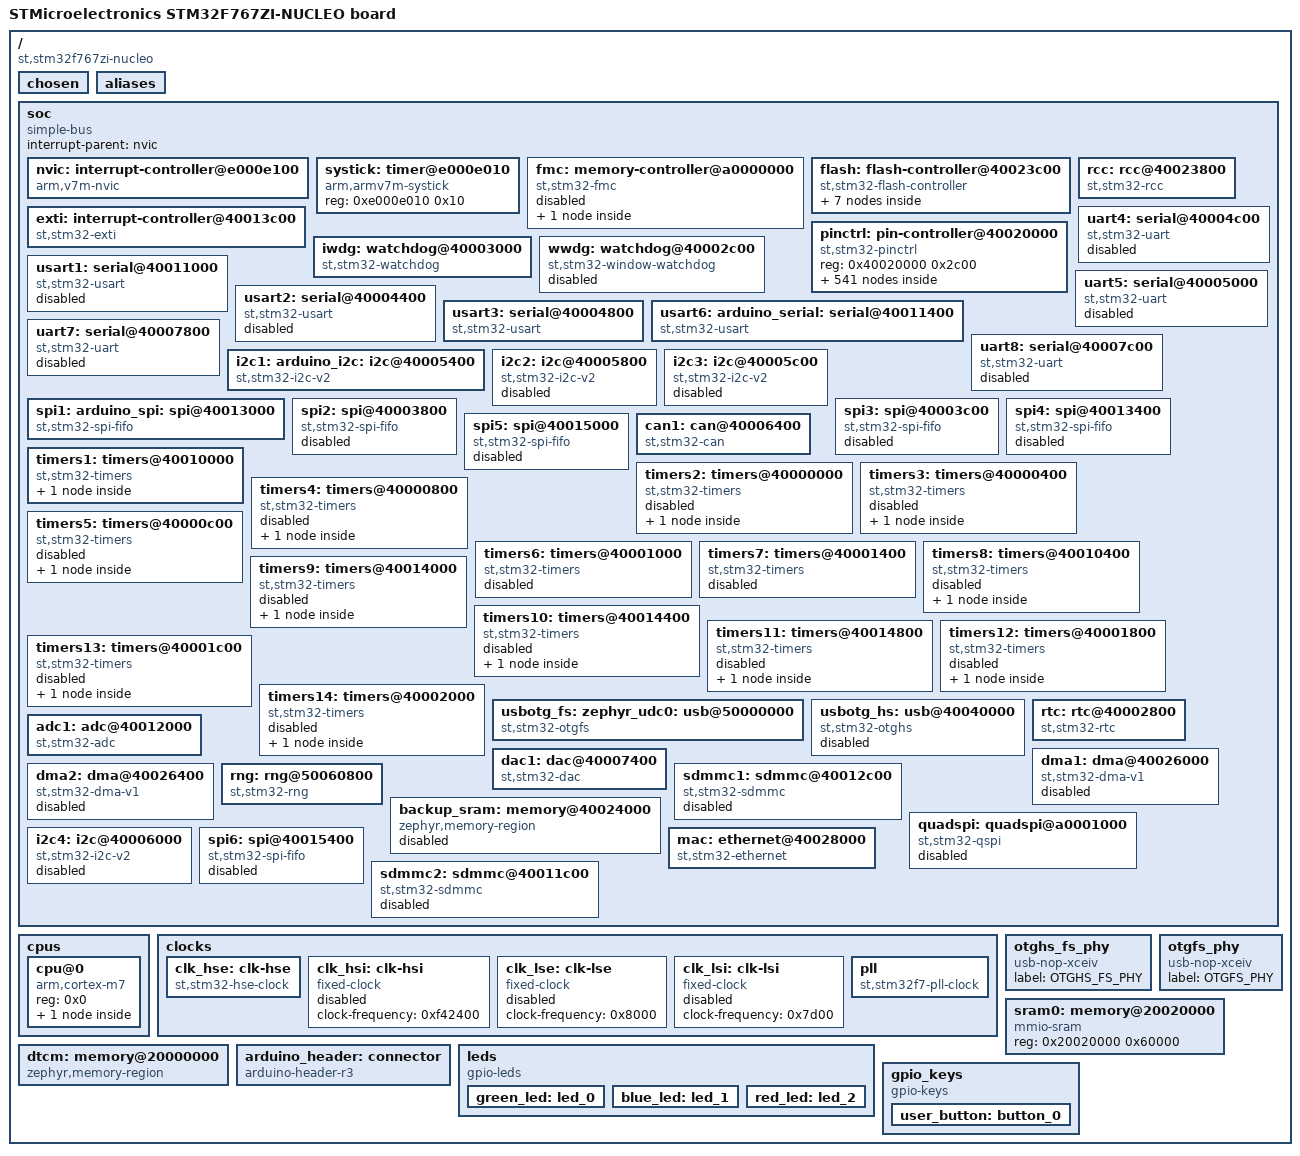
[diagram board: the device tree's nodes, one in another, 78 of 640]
/dts-v1/;

/ {
	#address-cells = < 0x1 >;
	#size-cells = < 0x1 >;
	model = "STMicroelectronics STM32F767ZI-NUCLEO board";
	compatible = "st,stm32f767zi-nucleo";
	chosen {
		zephyr,entropy = &rng;
		zephyr,flash-controller = &flash;
		zephyr,console = &usart3;
		zephyr,shell-uart = &usart3;
		zephyr,sram = &sram0;
		zephyr,flash = &flash0;
		zephyr,code-partition = &slot0_partition;
		zephyr,dtcm = &dtcm;
		zephyr,canbus = &can1;
	};
	aliases {
		led0 = &green_led;
		led1 = &blue_led;
		led2 = &red_led;
		sw0 = &user_button;
	};
	soc {
		#address-cells = < 0x1 >;
		#size-cells = < 0x1 >;
		compatible = "simple-bus";
		interrupt-parent = < &nvic >;
		ranges;
		nvic: interrupt-controller@e000e100 {
			#address-cells = < 0x1 >;
			compatible = "arm,v7m-nvic";
			reg = < 0xe000e100 0xc00 >;
			interrupt-controller;
			#interrupt-cells = < 0x2 >;
			arm,num-irq-priority-bits = < 0x4 >;
			phandle = < 0x1 >;
		};
		systick: timer@e000e010 {
			compatible = "arm,armv7m-systick";
			reg = < 0xe000e010 0x10 >;
		};
		fmc: memory-controller@a0000000 {
			compatible = "st,stm32-fmc";
			reg = < 0xa0000000 0x400 >;
			clocks = < &rcc 0x6 0x1 >;
			label = "STM32_FMC";
			status = "disabled";
			sdram: sdram {
				compatible = "st,stm32-fmc-sdram";
				#address-cells = < 0x1 >;
				#size-cells = < 0x0 >;
				label = "STM32_FMC_SDRAM";
				status = "disabled";
			};
		};
		flash: flash-controller@40023c00 {
			compatible = "st,stm32-flash-controller", "st,stm32f7-flash-controller";
			label = "FLASH_CTRL";
			reg = < 0x40023c00 0x400 >;
			interrupts = < 0x4 0x0 >;
			#address-cells = < 0x1 >;
			#size-cells = < 0x1 >;
			flash0: flash@8000000 {
				compatible = "st,stm32-nv-flash", "soc-nv-flash";
				label = "FLASH_STM32";
				write-block-size = < 0x1 >;
				max-erase-time = < 0xfa0 >;
				reg = < 0x8000000 0x200000 >;
				partitions {
					compatible = "fixed-partitions";
					#address-cells = < 0x1 >;
					#size-cells = < 0x1 >;
					boot_partition: partition@0 {
						label = "mcuboot";
						reg = < 0x0 0x10000 >;
						read-only;
					};
					storage_partition: partition@10000 {
						label = "storage";
						reg = < 0x10000 0x10000 >;
					};
					slot0_partition: partition@40000 {
						label = "image-0";
						reg = < 0x40000 0xc0000 >;
					};
					slot1_partition: partition@100000 {
						label = "image-1";
						reg = < 0x100000 0xc0000 >;
					};
					scratch_partition: partition@1C0000 {
						label = "image-scratch";
						reg = < 0x1c0000 0x40000 >;
					};
				};
			};
		};
		rcc: rcc@40023800 {
			compatible = "st,stm32-rcc";
			#clock-cells = < 0x2 >;
			reg = < 0x40023800 0x400 >;
			clocks = < &pll >;
			clock-frequency = < 0x44aa200 >;
			ahb-prescaler = < 0x1 >;
			apb1-prescaler = < 0x2 >;
			apb2-prescaler = < 0x1 >;
			phandle = < 0x2 >;
		};
		exti: interrupt-controller@40013c00 {
			compatible = "st,stm32-exti";
			interrupt-controller;
			#interrupt-cells = < 0x1 >;
			reg = < 0x40013c00 0x400 >;
		};
		pinctrl: pin-controller@40020000 {
			compatible = "st,stm32-pinctrl";
			#address-cells = < 0x1 >;
			#size-cells = < 0x1 >;
			reg = < 0x40020000 0x2c00 >;
			gpioa: gpio@40020000 {
				compatible = "st,stm32-gpio";
				gpio-controller;
				#gpio-cells = < 0x2 >;
				reg = < 0x40020000 0x400 >;
				clocks = < &rcc 0x0 0x1 >;
				label = "GPIOA";
				phandle = < 0x25 >;
			};
			gpiob: gpio@40020400 {
				compatible = "st,stm32-gpio";
				gpio-controller;
				#gpio-cells = < 0x2 >;
				reg = < 0x40020400 0x400 >;
				clocks = < &rcc 0x0 0x2 >;
				label = "GPIOB";
				phandle = < 0x2a >;
			};
			gpioc: gpio@40020800 {
				compatible = "st,stm32-gpio";
				gpio-controller;
				#gpio-cells = < 0x2 >;
				reg = < 0x40020800 0x400 >;
				clocks = < &rcc 0x0 0x4 >;
				label = "GPIOC";
				phandle = < 0x26 >;
			};
			gpiod: gpio@40020C00 {
				compatible = "st,stm32-gpio";
				gpio-controller;
				#gpio-cells = < 0x2 >;
				reg = < 0x40020c00 0x400 >;
				clocks = < &rcc 0x0 0x8 >;
				label = "GPIOD";
				phandle = < 0x11 >;
			};
			gpioe: gpio@40021000 {
				compatible = "st,stm32-gpio";
				gpio-controller;
				#gpio-cells = < 0x2 >;
				reg = < 0x40021000 0x400 >;
				clocks = < &rcc 0x0 0x10 >;
				label = "GPIOE";
				phandle = < 0x29 >;
			};
			gpiof: gpio@40021400 {
				compatible = "st,stm32-gpio";
				gpio-controller;
				#gpio-cells = < 0x2 >;
				reg = < 0x40021400 0x400 >;
				clocks = < &rcc 0x0 0x20 >;
				label = "GPIOF";
				phandle = < 0x27 >;
			};
			gpiog: gpio@40021800 {
				compatible = "st,stm32-gpio";
				gpio-controller;
				#gpio-cells = < 0x2 >;
				reg = < 0x40021800 0x400 >;
				clocks = < &rcc 0x0 0x40 >;
				label = "GPIOG";
				phandle = < 0x28 >;
			};
			gpioh: gpio@40021C00 {
				compatible = "st,stm32-gpio";
				gpio-controller;
				#gpio-cells = < 0x2 >;
				reg = < 0x40021c00 0x400 >;
				clocks = < &rcc 0x0 0x80 >;
				label = "GPIOH";
			};
			gpioi: gpio@40022000 {
				compatible = "st,stm32-gpio";
				gpio-controller;
				#gpio-cells = < 0x2 >;
				reg = < 0x40022000 0x400 >;
				clocks = < &rcc 0x0 0x100 >;
				label = "GPIOI";
			};
			gpioj: gpio@40022400 {
				compatible = "st,stm32-gpio";
				gpio-controller;
				#gpio-cells = < 0x2 >;
				reg = < 0x40022400 0x400 >;
				clocks = < &rcc 0x0 0x200 >;
				label = "GPIOJ";
			};
			gpiok: gpio@40022800 {
				compatible = "st,stm32-gpio";
				gpio-controller;
				#gpio-cells = < 0x2 >;
				reg = < 0x40022800 0x400 >;
				clocks = < &rcc 0x0 0x400 >;
				label = "GPIOK";
			};
			adc1_in0_pa0: adc1_in0_pa0 {
				pinmux = < 0x10 >;
				phandle = < 0x19 >;
			};
			adc1_in1_pa1: adc1_in1_pa1 {
				pinmux = < 0x30 >;
			};
			adc1_in2_pa2: adc1_in2_pa2 {
				pinmux = < 0x50 >;
			};
			adc1_in3_pa3: adc1_in3_pa3 {
				pinmux = < 0x70 >;
			};
			adc1_in4_pa4: adc1_in4_pa4 {
				pinmux = < 0x90 >;
			};
			adc1_in5_pa5: adc1_in5_pa5 {
				pinmux = < 0xb0 >;
			};
			adc1_in6_pa6: adc1_in6_pa6 {
				pinmux = < 0xd0 >;
			};
			adc1_in7_pa7: adc1_in7_pa7 {
				pinmux = < 0xf0 >;
			};
			adc1_in8_pb0: adc1_in8_pb0 {
				pinmux = < 0x210 >;
			};
			adc1_in9_pb1: adc1_in9_pb1 {
				pinmux = < 0x230 >;
			};
			adc1_in10_pc0: adc1_in10_pc0 {
				pinmux = < 0x410 >;
			};
			adc1_in11_pc1: adc1_in11_pc1 {
				pinmux = < 0x430 >;
			};
			adc1_in12_pc2: adc1_in12_pc2 {
				pinmux = < 0x450 >;
			};
			adc1_in13_pc3: adc1_in13_pc3 {
				pinmux = < 0x470 >;
			};
			adc1_in14_pc4: adc1_in14_pc4 {
				pinmux = < 0x490 >;
			};
			adc1_in15_pc5: adc1_in15_pc5 {
				pinmux = < 0x4b0 >;
			};
			adc2_in0_pa0: adc2_in0_pa0 {
				pinmux = < 0x10 >;
			};
			adc2_in1_pa1: adc2_in1_pa1 {
				pinmux = < 0x30 >;
			};
			adc2_in2_pa2: adc2_in2_pa2 {
				pinmux = < 0x50 >;
			};
			adc2_in3_pa3: adc2_in3_pa3 {
				pinmux = < 0x70 >;
			};
			adc2_in4_pa4: adc2_in4_pa4 {
				pinmux = < 0x90 >;
			};
			adc2_in5_pa5: adc2_in5_pa5 {
				pinmux = < 0xb0 >;
			};
			adc2_in6_pa6: adc2_in6_pa6 {
				pinmux = < 0xd0 >;
			};
			adc2_in7_pa7: adc2_in7_pa7 {
				pinmux = < 0xf0 >;
			};
			adc2_in8_pb0: adc2_in8_pb0 {
				pinmux = < 0x210 >;
			};
			adc2_in9_pb1: adc2_in9_pb1 {
				pinmux = < 0x230 >;
			};
			adc2_in10_pc0: adc2_in10_pc0 {
				pinmux = < 0x410 >;
			};
			adc2_in11_pc1: adc2_in11_pc1 {
				pinmux = < 0x430 >;
			};
			adc2_in12_pc2: adc2_in12_pc2 {
				pinmux = < 0x450 >;
			};
			adc2_in13_pc3: adc2_in13_pc3 {
				pinmux = < 0x470 >;
			};
			adc2_in14_pc4: adc2_in14_pc4 {
				pinmux = < 0x490 >;
			};
			adc2_in15_pc5: adc2_in15_pc5 {
				pinmux = < 0x4b0 >;
			};
			adc3_in0_pa0: adc3_in0_pa0 {
				pinmux = < 0x10 >;
			};
			adc3_in1_pa1: adc3_in1_pa1 {
				pinmux = < 0x30 >;
			};
			adc3_in2_pa2: adc3_in2_pa2 {
				pinmux = < 0x50 >;
			};
			adc3_in3_pa3: adc3_in3_pa3 {
				pinmux = < 0x70 >;
			};
			adc3_in10_pc0: adc3_in10_pc0 {
				pinmux = < 0x410 >;
			};
			adc3_in11_pc1: adc3_in11_pc1 {
				pinmux = < 0x430 >;
			};
			adc3_in12_pc2: adc3_in12_pc2 {
				pinmux = < 0x450 >;
			};
			adc3_in13_pc3: adc3_in13_pc3 {
				pinmux = < 0x470 >;
			};
			adc3_in9_pf3: adc3_in9_pf3 {
				pinmux = < 0xa70 >;
			};
			adc3_in14_pf4: adc3_in14_pf4 {
				pinmux = < 0xa90 >;
			};
			adc3_in15_pf5: adc3_in15_pf5 {
				pinmux = < 0xab0 >;
			};
			adc3_in4_pf6: adc3_in4_pf6 {
				pinmux = < 0xad0 >;
			};
			adc3_in5_pf7: adc3_in5_pf7 {
				pinmux = < 0xaf0 >;
			};
			adc3_in6_pf8: adc3_in6_pf8 {
				pinmux = < 0xb10 >;
			};
			adc3_in7_pf9: adc3_in7_pf9 {
				pinmux = < 0xb30 >;
			};
			adc3_in8_pf10: adc3_in8_pf10 {
				pinmux = < 0xb50 >;
			};
			can1_rx_pa11: can1_rx_pa11 {
				pinmux = < 0x169 >;
				bias-pull-up;
			};
			can1_rx_pb8: can1_rx_pb8 {
				pinmux = < 0x309 >;
				bias-pull-up;
			};
			can1_rx_pd0: can1_rx_pd0 {
				pinmux = < 0x609 >;
				bias-pull-up;
				phandle = < 0x12 >;
			};
			can2_rx_pb5: can2_rx_pb5 {
				pinmux = < 0x2a9 >;
				bias-pull-up;
			};
			can2_rx_pb12: can2_rx_pb12 {
				pinmux = < 0x389 >;
				bias-pull-up;
			};
			can3_rx_pa8: can3_rx_pa8 {
				pinmux = < 0x10b >;
				bias-pull-up;
			};
			can3_rx_pb3: can3_rx_pb3 {
				pinmux = < 0x26b >;
				bias-pull-up;
			};
			can1_tx_pa12: can1_tx_pa12 {
				pinmux = < 0x189 >;
			};
			can1_tx_pb9: can1_tx_pb9 {
				pinmux = < 0x329 >;
			};
			can1_tx_pd1: can1_tx_pd1 {
				pinmux = < 0x629 >;
				phandle = < 0x13 >;
			};
			can2_tx_pb6: can2_tx_pb6 {
				pinmux = < 0x2c9 >;
			};
			can2_tx_pb13: can2_tx_pb13 {
				pinmux = < 0x3a9 >;
			};
			can3_tx_pa15: can3_tx_pa15 {
				pinmux = < 0x1eb >;
			};
			can3_tx_pb4: can3_tx_pb4 {
				pinmux = < 0x28b >;
			};
			dac_out1_pa4: dac_out1_pa4 {
				pinmux = < 0x90 >;
				phandle = < 0x1a >;
			};
			dac_out2_pa5: dac_out2_pa5 {
				pinmux = < 0xb0 >;
			};
			eth_col_pa3: eth_col_pa3 {
				pinmux = < 0x6b >;
				slew-rate = "very-high-speed";
			};
			eth_crs_pa0: eth_crs_pa0 {
				pinmux = < 0xb >;
				slew-rate = "very-high-speed";
			};
			eth_crs_dv_pa7: eth_crs_dv_pa7 {
				pinmux = < 0xeb >;
				slew-rate = "very-high-speed";
				phandle = < 0x20 >;
			};
			eth_mdc_pc1: eth_mdc_pc1 {
				pinmux = < 0x42b >;
				slew-rate = "very-high-speed";
				phandle = < 0x1b >;
			};
			eth_mdio_pa2: eth_mdio_pa2 {
				pinmux = < 0x4b >;
				slew-rate = "very-high-speed";
				phandle = < 0x1f >;
			};
			eth_pps_out_pb5: eth_pps_out_pb5 {
				pinmux = < 0x2ab >;
				slew-rate = "very-high-speed";
			};
			eth_pps_out_pg8: eth_pps_out_pg8 {
				pinmux = < 0xd0b >;
				slew-rate = "very-high-speed";
			};
			eth_ref_clk_pa1: eth_ref_clk_pa1 {
				pinmux = < 0x2b >;
				slew-rate = "very-high-speed";
				phandle = < 0x1e >;
			};
			eth_rxd0_pc4: eth_rxd0_pc4 {
				pinmux = < 0x48b >;
				slew-rate = "very-high-speed";
				phandle = < 0x1c >;
			};
			eth_rxd1_pc5: eth_rxd1_pc5 {
				pinmux = < 0x4ab >;
				slew-rate = "very-high-speed";
				phandle = < 0x1d >;
			};
			eth_rxd2_pb0: eth_rxd2_pb0 {
				pinmux = < 0x20b >;
				slew-rate = "very-high-speed";
			};
			eth_rxd3_pb1: eth_rxd3_pb1 {
				pinmux = < 0x22b >;
				slew-rate = "very-high-speed";
			};
			eth_rx_clk_pa1: eth_rx_clk_pa1 {
				pinmux = < 0x2b >;
				slew-rate = "very-high-speed";
			};
			eth_rx_dv_pa7: eth_rx_dv_pa7 {
				pinmux = < 0xeb >;
				slew-rate = "very-high-speed";
			};
			eth_rx_er_pb10: eth_rx_er_pb10 {
				pinmux = < 0x34b >;
				slew-rate = "very-high-speed";
			};
			eth_txd0_pb12: eth_txd0_pb12 {
				pinmux = < 0x38b >;
				slew-rate = "very-high-speed";
			};
			eth_txd0_pg13: eth_txd0_pg13 {
				pinmux = < 0xdab >;
				slew-rate = "very-high-speed";
				phandle = < 0x22 >;
			};
			eth_txd1_pb13: eth_txd1_pb13 {
				pinmux = < 0x3ab >;
				slew-rate = "very-high-speed";
				phandle = < 0x23 >;
			};
			eth_txd1_pg14: eth_txd1_pg14 {
				pinmux = < 0xdcb >;
				slew-rate = "very-high-speed";
			};
			eth_txd2_pc2: eth_txd2_pc2 {
				pinmux = < 0x44b >;
				slew-rate = "very-high-speed";
			};
			eth_txd3_pb8: eth_txd3_pb8 {
				pinmux = < 0x30b >;
				slew-rate = "very-high-speed";
			};
			eth_txd3_pe2: eth_txd3_pe2 {
				pinmux = < 0x84b >;
				slew-rate = "very-high-speed";
			};
			eth_tx_clk_pc3: eth_tx_clk_pc3 {
				pinmux = < 0x46b >;
				slew-rate = "very-high-speed";
			};
			eth_tx_en_pb11: eth_tx_en_pb11 {
				pinmux = < 0x36b >;
				slew-rate = "very-high-speed";
			};
			eth_tx_en_pg11: eth_tx_en_pg11 {
				pinmux = < 0xd6b >;
				slew-rate = "very-high-speed";
				phandle = < 0x21 >;
			};
			fmc_sdnwe_pa7: fmc_sdnwe_pa7 {
				pinmux = < 0xec >;
				bias-pull-up;
				slew-rate = "very-high-speed";
			};
			fmc_sdcke1_pb5: fmc_sdcke1_pb5 {
				pinmux = < 0x2ac >;
				bias-pull-up;
				slew-rate = "very-high-speed";
			};
			fmc_sdne1_pb6: fmc_sdne1_pb6 {
				pinmux = < 0x2cc >;
				bias-pull-up;
				slew-rate = "very-high-speed";
			};
			fmc_nl_pb7: fmc_nl_pb7 {
				pinmux = < 0x2ec >;
				bias-pull-up;
				slew-rate = "very-high-speed";
			};
			fmc_sdnwe_pc0: fmc_sdnwe_pc0 {
				pinmux = < 0x40c >;
				bias-pull-up;
				slew-rate = "very-high-speed";
			};
			fmc_sdne0_pc2: fmc_sdne0_pc2 {
				pinmux = < 0x44c >;
				bias-pull-up;
				slew-rate = "very-high-speed";
			};
			fmc_sdcke0_pc3: fmc_sdcke0_pc3 {
				pinmux = < 0x46c >;
				bias-pull-up;
				slew-rate = "very-high-speed";
			};
			fmc_sdne0_pc4: fmc_sdne0_pc4 {
				pinmux = < 0x48c >;
				bias-pull-up;
				slew-rate = "very-high-speed";
			};
			fmc_sdcke0_pc5: fmc_sdcke0_pc5 {
				pinmux = < 0x4ac >;
				bias-pull-up;
				slew-rate = "very-high-speed";
			};
			fmc_nwait_pc6: fmc_nwait_pc6 {
				pinmux = < 0x4c9 >;
				bias-pull-up;
				slew-rate = "very-high-speed";
			};
			fmc_ne1_pc7: fmc_ne1_pc7 {
				pinmux = < 0x4e9 >;
				bias-pull-up;
				slew-rate = "very-high-speed";
			};
			fmc_nce_pc8: fmc_nce_pc8 {
				pinmux = < 0x509 >;
				bias-pull-up;
				slew-rate = "very-high-speed";
			};
			fmc_ne2_pc8: fmc_ne2_pc8 {
				pinmux = < 0x509 >;
				bias-pull-up;
				slew-rate = "very-high-speed";
			};
			fmc_d2_pd0: fmc_d2_pd0 {
				pinmux = < 0x60c >;
				bias-pull-up;
				slew-rate = "very-high-speed";
			};
			fmc_d3_pd1: fmc_d3_pd1 {
				pinmux = < 0x62c >;
				bias-pull-up;
				slew-rate = "very-high-speed";
			};
			fmc_clk_pd3: fmc_clk_pd3 {
				pinmux = < 0x66c >;
				bias-pull-up;
				slew-rate = "very-high-speed";
			};
			fmc_noe_pd4: fmc_noe_pd4 {
				pinmux = < 0x68c >;
				bias-pull-up;
				slew-rate = "very-high-speed";
			};
			fmc_nwe_pd5: fmc_nwe_pd5 {
				pinmux = < 0x6ac >;
				bias-pull-up;
				slew-rate = "very-high-speed";
			};
			fmc_nwait_pd6: fmc_nwait_pd6 {
				pinmux = < 0x6cc >;
				bias-pull-up;
				slew-rate = "very-high-speed";
			};
			fmc_ne1_pd7: fmc_ne1_pd7 {
				pinmux = < 0x6ec >;
				bias-pull-up;
				slew-rate = "very-high-speed";
			};
			fmc_d13_pd8: fmc_d13_pd8 {
				pinmux = < 0x70c >;
				bias-pull-up;
				slew-rate = "very-high-speed";
			};
			fmc_d14_pd9: fmc_d14_pd9 {
				pinmux = < 0x72c >;
				bias-pull-up;
				slew-rate = "very-high-speed";
			};
			fmc_d15_pd10: fmc_d15_pd10 {
				pinmux = < 0x74c >;
				bias-pull-up;
				slew-rate = "very-high-speed";
			};
			fmc_a16_pd11: fmc_a16_pd11 {
				pinmux = < 0x76c >;
				bias-pull-up;
				slew-rate = "very-high-speed";
			};
			fmc_a17_pd12: fmc_a17_pd12 {
				pinmux = < 0x78c >;
				bias-pull-up;
				slew-rate = "very-high-speed";
			};
			fmc_a18_pd13: fmc_a18_pd13 {
				pinmux = < 0x7ac >;
				bias-pull-up;
				slew-rate = "very-high-speed";
			};
			fmc_d0_pd14: fmc_d0_pd14 {
				pinmux = < 0x7cc >;
				bias-pull-up;
				slew-rate = "very-high-speed";
			};
			fmc_d1_pd15: fmc_d1_pd15 {
				pinmux = < 0x7ec >;
				bias-pull-up;
				slew-rate = "very-high-speed";
			};
			fmc_nbl0_pe0: fmc_nbl0_pe0 {
				pinmux = < 0x80c >;
				bias-pull-up;
				slew-rate = "very-high-speed";
			};
			fmc_nbl1_pe1: fmc_nbl1_pe1 {
				pinmux = < 0x82c >;
				bias-pull-up;
				slew-rate = "very-high-speed";
			};
			fmc_a23_pe2: fmc_a23_pe2 {
				pinmux = < 0x84c >;
				bias-pull-up;
				slew-rate = "very-high-speed";
			};
			fmc_a19_pe3: fmc_a19_pe3 {
				pinmux = < 0x86c >;
				bias-pull-up;
				slew-rate = "very-high-speed";
			};
			fmc_a20_pe4: fmc_a20_pe4 {
				pinmux = < 0x88c >;
				bias-pull-up;
				slew-rate = "very-high-speed";
			};
			fmc_a21_pe5: fmc_a21_pe5 {
				pinmux = < 0x8ac >;
				bias-pull-up;
				slew-rate = "very-high-speed";
			};
			fmc_a22_pe6: fmc_a22_pe6 {
				pinmux = < 0x8cc >;
				bias-pull-up;
				slew-rate = "very-high-speed";
			};
			fmc_d4_pe7: fmc_d4_pe7 {
				pinmux = < 0x8ec >;
				bias-pull-up;
				slew-rate = "very-high-speed";
			};
			fmc_d5_pe8: fmc_d5_pe8 {
				pinmux = < 0x90c >;
				bias-pull-up;
				slew-rate = "very-high-speed";
			};
			fmc_d6_pe9: fmc_d6_pe9 {
				pinmux = < 0x92c >;
				bias-pull-up;
				slew-rate = "very-high-speed";
			};
			fmc_d7_pe10: fmc_d7_pe10 {
				pinmux = < 0x94c >;
				bias-pull-up;
				slew-rate = "very-high-speed";
			};
			fmc_d8_pe11: fmc_d8_pe11 {
				pinmux = < 0x96c >;
				bias-pull-up;
				slew-rate = "very-high-speed";
			};
			fmc_d9_pe12: fmc_d9_pe12 {
				pinmux = < 0x98c >;
				bias-pull-up;
				slew-rate = "very-high-speed";
			};
			fmc_d10_pe13: fmc_d10_pe13 {
				pinmux = < 0x9ac >;
				bias-pull-up;
				slew-rate = "very-high-speed";
			};
			fmc_d11_pe14: fmc_d11_pe14 {
				pinmux = < 0x9cc >;
				bias-pull-up;
				slew-rate = "very-high-speed";
			};
			fmc_d12_pe15: fmc_d12_pe15 {
				pinmux = < 0x9ec >;
				bias-pull-up;
				slew-rate = "very-high-speed";
			};
			fmc_a0_pf0: fmc_a0_pf0 {
				pinmux = < 0xa0c >;
				bias-pull-up;
				slew-rate = "very-high-speed";
			};
			fmc_a1_pf1: fmc_a1_pf1 {
				pinmux = < 0xa2c >;
				bias-pull-up;
				slew-rate = "very-high-speed";
			};
			fmc_a2_pf2: fmc_a2_pf2 {
				pinmux = < 0xa4c >;
				bias-pull-up;
				slew-rate = "very-high-speed";
			};
			fmc_a3_pf3: fmc_a3_pf3 {
				pinmux = < 0xa6c >;
				bias-pull-up;
				slew-rate = "very-high-speed";
			};
			fmc_a4_pf4: fmc_a4_pf4 {
				pinmux = < 0xa8c >;
				bias-pull-up;
				slew-rate = "very-high-speed";
			};
			fmc_a5_pf5: fmc_a5_pf5 {
				pinmux = < 0xaac >;
				bias-pull-up;
				slew-rate = "very-high-speed";
			};
			fmc_sdnras_pf11: fmc_sdnras_pf11 {
				pinmux = < 0xb6c >;
				bias-pull-up;
				slew-rate = "very-high-speed";
			};
			fmc_a6_pf12: fmc_a6_pf12 {
				pinmux = < 0xb8c >;
				bias-pull-up;
				slew-rate = "very-high-speed";
			};
			fmc_a7_pf13: fmc_a7_pf13 {
				pinmux = < 0xbac >;
				bias-pull-up;
				slew-rate = "very-high-speed";
			};
			fmc_a8_pf14: fmc_a8_pf14 {
				pinmux = < 0xbcc >;
				bias-pull-up;
				slew-rate = "very-high-speed";
			};
			fmc_a9_pf15: fmc_a9_pf15 {
				pinmux = < 0xbec >;
				bias-pull-up;
				slew-rate = "very-high-speed";
			};
			fmc_a10_pg0: fmc_a10_pg0 {
				pinmux = < 0xc0c >;
				bias-pull-up;
				slew-rate = "very-high-speed";
			};
			fmc_a11_pg1: fmc_a11_pg1 {
				pinmux = < 0xc2c >;
				bias-pull-up;
				slew-rate = "very-high-speed";
			};
			fmc_a12_pg2: fmc_a12_pg2 {
				pinmux = < 0xc4c >;
				bias-pull-up;
				slew-rate = "very-high-speed";
			};
			fmc_a13_pg3: fmc_a13_pg3 {
				pinmux = < 0xc6c >;
				bias-pull-up;
				slew-rate = "very-high-speed";
			};
			fmc_a14_pg4: fmc_a14_pg4 {
				pinmux = < 0xc8c >;
				bias-pull-up;
				slew-rate = "very-high-speed";
			};
			fmc_a15_pg5: fmc_a15_pg5 {
				pinmux = < 0xcac >;
				bias-pull-up;
				slew-rate = "very-high-speed";
			};
			fmc_ne3_pg6: fmc_ne3_pg6 {
				pinmux = < 0xccc >;
				bias-pull-up;
				slew-rate = "very-high-speed";
			};
			fmc_int_pg7: fmc_int_pg7 {
				pinmux = < 0xcec >;
				bias-pull-up;
				slew-rate = "very-high-speed";
			};
			fmc_sdclk_pg8: fmc_sdclk_pg8 {
				pinmux = < 0xd0c >;
				bias-pull-up;
				slew-rate = "very-high-speed";
			};
			fmc_nce_pg9: fmc_nce_pg9 {
				pinmux = < 0xd2c >;
				bias-pull-up;
				slew-rate = "very-high-speed";
			};
			fmc_ne2_pg9: fmc_ne2_pg9 {
				pinmux = < 0xd2c >;
				bias-pull-up;
				slew-rate = "very-high-speed";
			};
			fmc_ne3_pg10: fmc_ne3_pg10 {
				pinmux = < 0xd4c >;
				bias-pull-up;
				slew-rate = "very-high-speed";
			};
			fmc_ne4_pg12: fmc_ne4_pg12 {
				pinmux = < 0xd8c >;
				bias-pull-up;
				slew-rate = "very-high-speed";
			};
			fmc_a24_pg13: fmc_a24_pg13 {
				pinmux = < 0xdac >;
				bias-pull-up;
				slew-rate = "very-high-speed";
			};
			fmc_a25_pg14: fmc_a25_pg14 {
				pinmux = < 0xdcc >;
				bias-pull-up;
				slew-rate = "very-high-speed";
			};
			fmc_sdncas_pg15: fmc_sdncas_pg15 {
				pinmux = < 0xdec >;
				bias-pull-up;
				slew-rate = "very-high-speed";
			};
			i2c1_scl_pb6: i2c1_scl_pb6 {
				pinmux = < 0x2c4 >;
				bias-pull-up;
				drive-open-drain;
			};
			i2c1_scl_pb8: i2c1_scl_pb8 {
				pinmux = < 0x304 >;
				bias-pull-up;
				drive-open-drain;
				phandle = < 0xc >;
			};
			i2c2_scl_pb10: i2c2_scl_pb10 {
				pinmux = < 0x344 >;
				bias-pull-up;
				drive-open-drain;
			};
			i2c2_scl_pf1: i2c2_scl_pf1 {
				pinmux = < 0xa24 >;
				bias-pull-up;
				drive-open-drain;
			};
			i2c3_scl_pa8: i2c3_scl_pa8 {
				pinmux = < 0x104 >;
				bias-pull-up;
				drive-open-drain;
			};
			i2c4_scl_pb6: i2c4_scl_pb6 {
				pinmux = < 0x2cb >;
				bias-pull-up;
				drive-open-drain;
			};
			i2c4_scl_pb8: i2c4_scl_pb8 {
				pinmux = < 0x301 >;
				bias-pull-up;
				drive-open-drain;
			};
			i2c4_scl_pd12: i2c4_scl_pd12 {
				pinmux = < 0x784 >;
				bias-pull-up;
				drive-open-drain;
			};
			i2c4_scl_pf14: i2c4_scl_pf14 {
				pinmux = < 0xbc4 >;
				bias-pull-up;
				drive-open-drain;
			};
			i2c1_sda_pb7: i2c1_sda_pb7 {
				pinmux = < 0x2e4 >;
				bias-pull-up;
				drive-open-drain;
			};
			i2c1_sda_pb9: i2c1_sda_pb9 {
				pinmux = < 0x324 >;
				bias-pull-up;
				drive-open-drain;
				phandle = < 0xd >;
			};
			i2c2_sda_pb11: i2c2_sda_pb11 {
				pinmux = < 0x364 >;
				bias-pull-up;
				drive-open-drain;
			};
			i2c2_sda_pf0: i2c2_sda_pf0 {
				pinmux = < 0xa04 >;
				bias-pull-up;
				drive-open-drain;
			};
			i2c3_sda_pc9: i2c3_sda_pc9 {
				pinmux = < 0x524 >;
				bias-pull-up;
				drive-open-drain;
			};
			i2c4_sda_pb7: i2c4_sda_pb7 {
				pinmux = < 0x2eb >;
				bias-pull-up;
				drive-open-drain;
			};
			i2c4_sda_pb9: i2c4_sda_pb9 {
				pinmux = < 0x321 >;
				bias-pull-up;
				drive-open-drain;
			};
			i2c4_sda_pd13: i2c4_sda_pd13 {
				pinmux = < 0x7a4 >;
				bias-pull-up;
				drive-open-drain;
			};
			i2c4_sda_pf15: i2c4_sda_pf15 {
				pinmux = < 0xbe4 >;
				bias-pull-up;
				drive-open-drain;
			};
			i2s1_ck_pa5: i2s1_ck_pa5 {
				pinmux = < 0xa5 >;
				slew-rate = "very-high-speed";
			};
			i2s1_ck_pb3: i2s1_ck_pb3 {
				pinmux = < 0x265 >;
				slew-rate = "very-high-speed";
			};
			i2s1_ck_pg11: i2s1_ck_pg11 {
				pinmux = < 0xd65 >;
				slew-rate = "very-high-speed";
			};
			i2s2_ck_pa9: i2s2_ck_pa9 {
				pinmux = < 0x125 >;
				slew-rate = "very-high-speed";
			};
			i2s2_ck_pa12: i2s2_ck_pa12 {
				pinmux = < 0x185 >;
				slew-rate = "very-high-speed";
			};
			i2s2_ck_pb10: i2s2_ck_pb10 {
				pinmux = < 0x345 >;
				slew-rate = "very-high-speed";
			};
			i2s2_ck_pb13: i2s2_ck_pb13 {
				pinmux = < 0x3a5 >;
				slew-rate = "very-high-speed";
			};
			i2s2_ck_pd3: i2s2_ck_pd3 {
				pinmux = < 0x665 >;
				slew-rate = "very-high-speed";
			};
			i2s3_ck_pb3: i2s3_ck_pb3 {
				pinmux = < 0x266 >;
				slew-rate = "very-high-speed";
			};
			i2s3_ck_pc10: i2s3_ck_pc10 {
				pinmux = < 0x546 >;
				slew-rate = "very-high-speed";
			};
			i2s1_sd_pa7: i2s1_sd_pa7 {
				pinmux = < 0xe5 >;
			};
			i2s1_sd_pb5: i2s1_sd_pb5 {
				pinmux = < 0x2a5 >;
			};
			i2s1_sd_pd7: i2s1_sd_pd7 {
				pinmux = < 0x6e5 >;
			};
			i2s2_sd_pb15: i2s2_sd_pb15 {
				pinmux = < 0x3e5 >;
			};
			i2s2_sd_pc1: i2s2_sd_pc1 {
				pinmux = < 0x425 >;
			};
			i2s2_sd_pc3: i2s2_sd_pc3 {
				pinmux = < 0x465 >;
			};
			i2s3_sd_pb2: i2s3_sd_pb2 {
				pinmux = < 0x247 >;
			};
			i2s3_sd_pb5: i2s3_sd_pb5 {
				pinmux = < 0x2a6 >;
			};
			i2s3_sd_pc12: i2s3_sd_pc12 {
				pinmux = < 0x586 >;
			};
			i2s3_sd_pd6: i2s3_sd_pd6 {
				pinmux = < 0x6c5 >;
			};
			i2s1_ws_pa4: i2s1_ws_pa4 {
				pinmux = < 0x85 >;
			};
			i2s1_ws_pa15: i2s1_ws_pa15 {
				pinmux = < 0x1e5 >;
			};
			i2s1_ws_pg10: i2s1_ws_pg10 {
				pinmux = < 0xd45 >;
			};
			i2s2_ws_pa11: i2s2_ws_pa11 {
				pinmux = < 0x165 >;
			};
			i2s2_ws_pb4: i2s2_ws_pb4 {
				pinmux = < 0x287 >;
			};
			i2s2_ws_pb9: i2s2_ws_pb9 {
				pinmux = < 0x325 >;
			};
			i2s2_ws_pb12: i2s2_ws_pb12 {
				pinmux = < 0x385 >;
			};
			i2s3_ws_pa4: i2s3_ws_pa4 {
				pinmux = < 0x86 >;
			};
			i2s3_ws_pa15: i2s3_ws_pa15 {
				pinmux = < 0x1e6 >;
			};
			ltdc_r2_pa1: ltdc_r2_pa1 {
				pinmux = < 0x2e >;
			};
			ltdc_r1_pa2: ltdc_r1_pa2 {
				pinmux = < 0x4e >;
			};
			ltdc_b2_pa3: ltdc_b2_pa3 {
				pinmux = < 0x69 >;
			};
			ltdc_b5_pa3: ltdc_b5_pa3 {
				pinmux = < 0x6e >;
			};
			ltdc_vsync_pa4: ltdc_vsync_pa4 {
				pinmux = < 0x8e >;
			};
			ltdc_r4_pa5: ltdc_r4_pa5 {
				pinmux = < 0xae >;
			};
			ltdc_g2_pa6: ltdc_g2_pa6 {
				pinmux = < 0xce >;
			};
			ltdc_b3_pa8: ltdc_b3_pa8 {
				pinmux = < 0x10d >;
			};
			ltdc_r6_pa8: ltdc_r6_pa8 {
				pinmux = < 0x10e >;
			};
			ltdc_r5_pa9: ltdc_r5_pa9 {
				pinmux = < 0x12e >;
			};
			ltdc_b1_pa10: ltdc_b1_pa10 {
				pinmux = < 0x14e >;
			};
			ltdc_b4_pa10: ltdc_b4_pa10 {
				pinmux = < 0x149 >;
			};
			ltdc_r4_pa11: ltdc_r4_pa11 {
				pinmux = < 0x16e >;
			};
			ltdc_r5_pa12: ltdc_r5_pa12 {
				pinmux = < 0x18e >;
			};
			ltdc_g1_pb0: ltdc_g1_pb0 {
				pinmux = < 0x20e >;
			};
			ltdc_r3_pb0: ltdc_r3_pb0 {
				pinmux = < 0x209 >;
			};
			ltdc_g0_pb1: ltdc_g0_pb1 {
				pinmux = < 0x22e >;
			};
			ltdc_r6_pb1: ltdc_r6_pb1 {
				pinmux = < 0x229 >;
			};
			ltdc_g7_pb5: ltdc_g7_pb5 {
				pinmux = < 0x2ae >;
			};
			ltdc_b6_pb8: ltdc_b6_pb8 {
				pinmux = < 0x30e >;
			};
			ltdc_b7_pb9: ltdc_b7_pb9 {
				pinmux = < 0x32e >;
			};
			ltdc_g4_pb10: ltdc_g4_pb10 {
				pinmux = < 0x34e >;
			};
			ltdc_g5_pb11: ltdc_g5_pb11 {
				pinmux = < 0x36e >;
			};
			ltdc_r5_pc0: ltdc_r5_pc0 {
				pinmux = < 0x40e >;
			};
			ltdc_hsync_pc6: ltdc_hsync_pc6 {
				pinmux = < 0x4ce >;
			};
			ltdc_g6_pc7: ltdc_g6_pc7 {
				pinmux = < 0x4ee >;
			};
			ltdc_b2_pc9: ltdc_b2_pc9 {
				pinmux = < 0x52e >;
			};
			ltdc_g3_pc9: ltdc_g3_pc9 {
				pinmux = < 0x52a >;
			};
			ltdc_r2_pc10: ltdc_r2_pc10 {
				pinmux = < 0x54e >;
			};
			ltdc_g7_pd3: ltdc_g7_pd3 {
				pinmux = < 0x66e >;
			};
			ltdc_b2_pd6: ltdc_b2_pd6 {
				pinmux = < 0x6ce >;
			};
			ltdc_b3_pd10: ltdc_b3_pd10 {
				pinmux = < 0x74e >;
			};
			ltdc_b0_pe4: ltdc_b0_pe4 {
				pinmux = < 0x88e >;
			};
			ltdc_g0_pe5: ltdc_g0_pe5 {
				pinmux = < 0x8ae >;
			};
			ltdc_g1_pe6: ltdc_g1_pe6 {
				pinmux = < 0x8ce >;
			};
			ltdc_g3_pe11: ltdc_g3_pe11 {
				pinmux = < 0x96e >;
			};
			ltdc_b4_pe12: ltdc_b4_pe12 {
				pinmux = < 0x98e >;
			};
			ltdc_de_pe13: ltdc_de_pe13 {
				pinmux = < 0x9ae >;
			};
			ltdc_clk_pe14: ltdc_clk_pe14 {
				pinmux = < 0x9ce >;
			};
			ltdc_r7_pe15: ltdc_r7_pe15 {
				pinmux = < 0x9ee >;
			};
			ltdc_de_pf10: ltdc_de_pf10 {
				pinmux = < 0xb4e >;
			};
			ltdc_r7_pg6: ltdc_r7_pg6 {
				pinmux = < 0xcce >;
			};
			ltdc_clk_pg7: ltdc_clk_pg7 {
				pinmux = < 0xcee >;
			};
			ltdc_g7_pg8: ltdc_g7_pg8 {
				pinmux = < 0xd0e >;
			};
			ltdc_b2_pg10: ltdc_b2_pg10 {
				pinmux = < 0xd4e >;
			};
			ltdc_g3_pg10: ltdc_g3_pg10 {
				pinmux = < 0xd49 >;
			};
			ltdc_b3_pg11: ltdc_b3_pg11 {
				pinmux = < 0xd6e >;
			};
			ltdc_b1_pg12: ltdc_b1_pg12 {
				pinmux = < 0xd8e >;
			};
			ltdc_b4_pg12: ltdc_b4_pg12 {
				pinmux = < 0xd89 >;
			};
			ltdc_r0_pg13: ltdc_r0_pg13 {
				pinmux = < 0xdae >;
			};
			ltdc_b0_pg14: ltdc_b0_pg14 {
				pinmux = < 0xdce >;
			};
			quadspi_bk1_io3_pa1: quadspi_bk1_io3_pa1 {
				pinmux = < 0x29 >;
				slew-rate = "very-high-speed";
			};
			quadspi_clk_pb2: quadspi_clk_pb2 {
				pinmux = < 0x249 >;
				slew-rate = "very-high-speed";
			};
			quadspi_bk1_ncs_pb6: quadspi_bk1_ncs_pb6 {
				pinmux = < 0x2ca >;
				slew-rate = "very-high-speed";
			};
			quadspi_bk1_ncs_pb10: quadspi_bk1_ncs_pb10 {
				pinmux = < 0x349 >;
				slew-rate = "very-high-speed";
			};
			quadspi_bk1_io0_pc9: quadspi_bk1_io0_pc9 {
				pinmux = < 0x529 >;
				slew-rate = "very-high-speed";
			};
			quadspi_bk1_io1_pc10: quadspi_bk1_io1_pc10 {
				pinmux = < 0x549 >;
				slew-rate = "very-high-speed";
			};
			quadspi_bk2_ncs_pc11: quadspi_bk2_ncs_pc11 {
				pinmux = < 0x569 >;
				slew-rate = "very-high-speed";
			};
			quadspi_bk1_io0_pd11: quadspi_bk1_io0_pd11 {
				pinmux = < 0x769 >;
				slew-rate = "very-high-speed";
			};
			quadspi_bk1_io1_pd12: quadspi_bk1_io1_pd12 {
				pinmux = < 0x789 >;
				slew-rate = "very-high-speed";
			};
			quadspi_bk1_io3_pd13: quadspi_bk1_io3_pd13 {
				pinmux = < 0x7a9 >;
				slew-rate = "very-high-speed";
			};
			quadspi_bk1_io2_pe2: quadspi_bk1_io2_pe2 {
				pinmux = < 0x849 >;
				slew-rate = "very-high-speed";
			};
			quadspi_bk2_io0_pe7: quadspi_bk2_io0_pe7 {
				pinmux = < 0x8ea >;
				slew-rate = "very-high-speed";
			};
			quadspi_bk2_io1_pe8: quadspi_bk2_io1_pe8 {
				pinmux = < 0x90a >;
				slew-rate = "very-high-speed";
			};
			quadspi_bk2_io2_pe9: quadspi_bk2_io2_pe9 {
				pinmux = < 0x92a >;
				slew-rate = "very-high-speed";
			};
			quadspi_bk2_io3_pe10: quadspi_bk2_io3_pe10 {
				pinmux = < 0x94a >;
				slew-rate = "very-high-speed";
			};
			quadspi_bk1_io3_pf6: quadspi_bk1_io3_pf6 {
				pinmux = < 0xac9 >;
				slew-rate = "very-high-speed";
			};
			quadspi_bk1_io2_pf7: quadspi_bk1_io2_pf7 {
				pinmux = < 0xae9 >;
				slew-rate = "very-high-speed";
			};
			quadspi_bk1_io0_pf8: quadspi_bk1_io0_pf8 {
				pinmux = < 0xb0a >;
				slew-rate = "very-high-speed";
			};
			quadspi_bk1_io1_pf9: quadspi_bk1_io1_pf9 {
				pinmux = < 0xb2a >;
				slew-rate = "very-high-speed";
			};
			quadspi_clk_pf10: quadspi_clk_pf10 {
				pinmux = < 0xb49 >;
				slew-rate = "very-high-speed";
			};
			quadspi_bk2_io2_pg9: quadspi_bk2_io2_pg9 {
				pinmux = < 0xd29 >;
				slew-rate = "very-high-speed";
			};
			quadspi_bk2_io3_pg14: quadspi_bk2_io3_pg14 {
				pinmux = < 0xdc9 >;
				slew-rate = "very-high-speed";
			};
			sdmmc1_d4_pb8: sdmmc1_d4_pb8 {
				pinmux = < 0x30c >;
				bias-pull-up;
				slew-rate = "very-high-speed";
			};
			sdmmc1_d5_pb9: sdmmc1_d5_pb9 {
				pinmux = < 0x32c >;
				bias-pull-up;
				slew-rate = "very-high-speed";
			};
			sdmmc1_d6_pc6: sdmmc1_d6_pc6 {
				pinmux = < 0x4cc >;
				bias-pull-up;
				slew-rate = "very-high-speed";
			};
			sdmmc1_d7_pc7: sdmmc1_d7_pc7 {
				pinmux = < 0x4ec >;
				bias-pull-up;
				slew-rate = "very-high-speed";
			};
			sdmmc1_d0_pc8: sdmmc1_d0_pc8 {
				pinmux = < 0x50c >;
				bias-pull-up;
				slew-rate = "very-high-speed";
			};
			sdmmc1_d1_pc9: sdmmc1_d1_pc9 {
				pinmux = < 0x52c >;
				bias-pull-up;
				slew-rate = "very-high-speed";
			};
			sdmmc1_d2_pc10: sdmmc1_d2_pc10 {
				pinmux = < 0x54c >;
				bias-pull-up;
				slew-rate = "very-high-speed";
			};
			sdmmc1_d3_pc11: sdmmc1_d3_pc11 {
				pinmux = < 0x56c >;
				bias-pull-up;
				slew-rate = "very-high-speed";
			};
			sdmmc1_ck_pc12: sdmmc1_ck_pc12 {
				pinmux = < 0x58c >;
				bias-pull-up;
				slew-rate = "very-high-speed";
			};
			sdmmc1_cmd_pd2: sdmmc1_cmd_pd2 {
				pinmux = < 0x64c >;
				bias-pull-up;
				slew-rate = "very-high-speed";
			};
			sdmmc2_d2_pb3: sdmmc2_d2_pb3 {
				pinmux = < 0x26a >;
				bias-pull-up;
				slew-rate = "very-high-speed";
			};
			sdmmc2_d3_pb4: sdmmc2_d3_pb4 {
				pinmux = < 0x28a >;
				bias-pull-up;
				slew-rate = "very-high-speed";
			};
			sdmmc2_d4_pb8: sdmmc2_d4_pb8 {
				pinmux = < 0x30a >;
				bias-pull-up;
				slew-rate = "very-high-speed";
			};
			sdmmc2_d5_pb9: sdmmc2_d5_pb9 {
				pinmux = < 0x32a >;
				bias-pull-up;
				slew-rate = "very-high-speed";
			};
			sdmmc2_d0_pb14: sdmmc2_d0_pb14 {
				pinmux = < 0x3ca >;
				bias-pull-up;
				slew-rate = "very-high-speed";
			};
			sdmmc2_d1_pb15: sdmmc2_d1_pb15 {
				pinmux = < 0x3ea >;
				bias-pull-up;
				slew-rate = "very-high-speed";
			};
			sdmmc2_d6_pc6: sdmmc2_d6_pc6 {
				pinmux = < 0x4ca >;
				bias-pull-up;
				slew-rate = "very-high-speed";
			};
			sdmmc2_d7_pc7: sdmmc2_d7_pc7 {
				pinmux = < 0x4ea >;
				bias-pull-up;
				slew-rate = "very-high-speed";
			};
			sdmmc2_ck_pd6: sdmmc2_ck_pd6 {
				pinmux = < 0x6cb >;
				bias-pull-up;
				slew-rate = "very-high-speed";
			};
			sdmmc2_cmd_pd7: sdmmc2_cmd_pd7 {
				pinmux = < 0x6eb >;
				bias-pull-up;
				slew-rate = "very-high-speed";
			};
			sdmmc2_d0_pg9: sdmmc2_d0_pg9 {
				pinmux = < 0xd2b >;
				bias-pull-up;
				slew-rate = "very-high-speed";
			};
			sdmmc2_d1_pg10: sdmmc2_d1_pg10 {
				pinmux = < 0xd4b >;
				bias-pull-up;
				slew-rate = "very-high-speed";
			};
			sdmmc2_d2_pg11: sdmmc2_d2_pg11 {
				pinmux = < 0xd6a >;
				bias-pull-up;
				slew-rate = "very-high-speed";
			};
			sdmmc2_d3_pg12: sdmmc2_d3_pg12 {
				pinmux = < 0xd8b >;
				bias-pull-up;
				slew-rate = "very-high-speed";
			};
			spi1_miso_pa6: spi1_miso_pa6 {
				pinmux = < 0xc5 >;
				bias-pull-down;
				phandle = < 0xf >;
			};
			spi1_miso_pb4: spi1_miso_pb4 {
				pinmux = < 0x285 >;
				bias-pull-down;
			};
			spi1_miso_pg9: spi1_miso_pg9 {
				pinmux = < 0xd25 >;
				bias-pull-down;
			};
			spi2_miso_pb14: spi2_miso_pb14 {
				pinmux = < 0x3c5 >;
				bias-pull-down;
			};
			spi2_miso_pc2: spi2_miso_pc2 {
				pinmux = < 0x445 >;
				bias-pull-down;
			};
			spi3_miso_pb4: spi3_miso_pb4 {
				pinmux = < 0x286 >;
				bias-pull-down;
			};
			spi3_miso_pc11: spi3_miso_pc11 {
				pinmux = < 0x566 >;
				bias-pull-down;
			};
			spi4_miso_pe5: spi4_miso_pe5 {
				pinmux = < 0x8a5 >;
				bias-pull-down;
			};
			spi4_miso_pe13: spi4_miso_pe13 {
				pinmux = < 0x9a5 >;
				bias-pull-down;
			};
			spi5_miso_pf8: spi5_miso_pf8 {
				pinmux = < 0xb05 >;
				bias-pull-down;
			};
			spi6_miso_pa6: spi6_miso_pa6 {
				pinmux = < 0xc8 >;
				bias-pull-down;
			};
			spi6_miso_pb4: spi6_miso_pb4 {
				pinmux = < 0x288 >;
				bias-pull-down;
			};
			spi6_miso_pg12: spi6_miso_pg12 {
				pinmux = < 0xd85 >;
				bias-pull-down;
			};
			spi1_mosi_pa7: spi1_mosi_pa7 {
				pinmux = < 0xe5 >;
				bias-pull-down;
				phandle = < 0x10 >;
			};
			spi1_mosi_pb5: spi1_mosi_pb5 {
				pinmux = < 0x2a5 >;
				bias-pull-down;
			};
			spi1_mosi_pd7: spi1_mosi_pd7 {
				pinmux = < 0x6e5 >;
				bias-pull-down;
			};
			spi2_mosi_pb15: spi2_mosi_pb15 {
				pinmux = < 0x3e5 >;
				bias-pull-down;
			};
			spi2_mosi_pc1: spi2_mosi_pc1 {
				pinmux = < 0x425 >;
				bias-pull-down;
			};
			spi2_mosi_pc3: spi2_mosi_pc3 {
				pinmux = < 0x465 >;
				bias-pull-down;
			};
			spi3_mosi_pb2: spi3_mosi_pb2 {
				pinmux = < 0x247 >;
				bias-pull-down;
			};
			spi3_mosi_pb5: spi3_mosi_pb5 {
				pinmux = < 0x2a6 >;
				bias-pull-down;
			};
			spi3_mosi_pc12: spi3_mosi_pc12 {
				pinmux = < 0x586 >;
				bias-pull-down;
			};
			spi3_mosi_pd6: spi3_mosi_pd6 {
				pinmux = < 0x6c5 >;
				bias-pull-down;
			};
			spi4_mosi_pe6: spi4_mosi_pe6 {
				pinmux = < 0x8c5 >;
				bias-pull-down;
			};
			spi4_mosi_pe14: spi4_mosi_pe14 {
				pinmux = < 0x9c5 >;
				bias-pull-down;
			};
			spi5_mosi_pf9: spi5_mosi_pf9 {
				pinmux = < 0xb25 >;
				bias-pull-down;
			};
			spi5_mosi_pf11: spi5_mosi_pf11 {
				pinmux = < 0xb65 >;
				bias-pull-down;
			};
			spi6_mosi_pa7: spi6_mosi_pa7 {
				pinmux = < 0xe8 >;
				bias-pull-down;
			};
			spi6_mosi_pb5: spi6_mosi_pb5 {
				pinmux = < 0x2a8 >;
				bias-pull-down;
			};
			spi6_mosi_pg14: spi6_mosi_pg14 {
				pinmux = < 0xdc5 >;
				bias-pull-down;
			};
			spi1_nss_pa4: spi1_nss_pa4 {
				pinmux = < 0x85 >;
				bias-pull-up;
			};
			spi1_nss_pa15: spi1_nss_pa15 {
				pinmux = < 0x1e5 >;
				bias-pull-up;
			};
			spi1_nss_pg10: spi1_nss_pg10 {
				pinmux = < 0xd45 >;
				bias-pull-up;
			};
			spi2_nss_pa11: spi2_nss_pa11 {
				pinmux = < 0x165 >;
				bias-pull-up;
			};
			spi2_nss_pb4: spi2_nss_pb4 {
				pinmux = < 0x287 >;
				bias-pull-up;
			};
			spi2_nss_pb9: spi2_nss_pb9 {
				pinmux = < 0x325 >;
				bias-pull-up;
			};
			spi2_nss_pb12: spi2_nss_pb12 {
				pinmux = < 0x385 >;
				bias-pull-up;
			};
			spi3_nss_pa4: spi3_nss_pa4 {
				pinmux = < 0x86 >;
				bias-pull-up;
			};
			spi3_nss_pa15: spi3_nss_pa15 {
				pinmux = < 0x1e6 >;
				bias-pull-up;
			};
			spi4_nss_pe4: spi4_nss_pe4 {
				pinmux = < 0x885 >;
				bias-pull-up;
			};
			spi4_nss_pe11: spi4_nss_pe11 {
				pinmux = < 0x965 >;
				bias-pull-up;
			};
			spi5_nss_pf6: spi5_nss_pf6 {
				pinmux = < 0xac5 >;
				bias-pull-up;
			};
			spi6_nss_pa4: spi6_nss_pa4 {
				pinmux = < 0x88 >;
				bias-pull-up;
			};
			spi6_nss_pa15: spi6_nss_pa15 {
				pinmux = < 0x1e7 >;
				bias-pull-up;
			};
			spi6_nss_pg8: spi6_nss_pg8 {
				pinmux = < 0xd05 >;
				bias-pull-up;
			};
			spi1_sck_pa5: spi1_sck_pa5 {
				pinmux = < 0xa5 >;
				bias-pull-down;
				slew-rate = "very-high-speed";
				phandle = < 0xe >;
			};
			spi1_sck_pb3: spi1_sck_pb3 {
				pinmux = < 0x265 >;
				bias-pull-down;
				slew-rate = "very-high-speed";
			};
			spi1_sck_pg11: spi1_sck_pg11 {
				pinmux = < 0xd65 >;
				bias-pull-down;
				slew-rate = "very-high-speed";
			};
			spi2_sck_pa9: spi2_sck_pa9 {
				pinmux = < 0x125 >;
				bias-pull-down;
				slew-rate = "very-high-speed";
			};
			spi2_sck_pa12: spi2_sck_pa12 {
				pinmux = < 0x185 >;
				bias-pull-down;
				slew-rate = "very-high-speed";
			};
			spi2_sck_pb10: spi2_sck_pb10 {
				pinmux = < 0x345 >;
				bias-pull-down;
				slew-rate = "very-high-speed";
			};
			spi2_sck_pb13: spi2_sck_pb13 {
				pinmux = < 0x3a5 >;
				bias-pull-down;
				slew-rate = "very-high-speed";
			};
			spi2_sck_pd3: spi2_sck_pd3 {
				pinmux = < 0x665 >;
				bias-pull-down;
				slew-rate = "very-high-speed";
			};
			spi3_sck_pb3: spi3_sck_pb3 {
				pinmux = < 0x266 >;
				bias-pull-down;
				slew-rate = "very-high-speed";
			};
			spi3_sck_pc10: spi3_sck_pc10 {
				pinmux = < 0x546 >;
				bias-pull-down;
				slew-rate = "very-high-speed";
			};
			spi4_sck_pe2: spi4_sck_pe2 {
				pinmux = < 0x845 >;
				bias-pull-down;
				slew-rate = "very-high-speed";
			};
			spi4_sck_pe12: spi4_sck_pe12 {
				pinmux = < 0x985 >;
				bias-pull-down;
				slew-rate = "very-high-speed";
			};
			spi5_sck_pf7: spi5_sck_pf7 {
				pinmux = < 0xae5 >;
				bias-pull-down;
				slew-rate = "very-high-speed";
			};
			spi6_sck_pa5: spi6_sck_pa5 {
				pinmux = < 0xa8 >;
				bias-pull-down;
				slew-rate = "very-high-speed";
			};
			spi6_sck_pb3: spi6_sck_pb3 {
				pinmux = < 0x268 >;
				bias-pull-down;
				slew-rate = "very-high-speed";
			};
			spi6_sck_pg13: spi6_sck_pg13 {
				pinmux = < 0xda5 >;
				bias-pull-down;
				slew-rate = "very-high-speed";
			};
			tim10_ch1_pb8: tim10_ch1_pb8 {
				pinmux = < 0x303 >;
			};
			tim10_ch1_pf6: tim10_ch1_pf6 {
				pinmux = < 0xac3 >;
			};
			tim1_ch1n_pa7: tim1_ch1n_pa7 {
				pinmux = < 0xe1 >;
			};
			tim1_ch1_pa8: tim1_ch1_pa8 {
				pinmux = < 0x101 >;
			};
			tim1_ch2_pa9: tim1_ch2_pa9 {
				pinmux = < 0x121 >;
			};
			tim1_ch3_pa10: tim1_ch3_pa10 {
				pinmux = < 0x141 >;
			};
			tim1_ch4_pa11: tim1_ch4_pa11 {
				pinmux = < 0x161 >;
			};
			tim1_ch2n_pb0: tim1_ch2n_pb0 {
				pinmux = < 0x201 >;
			};
			tim1_ch3n_pb1: tim1_ch3n_pb1 {
				pinmux = < 0x221 >;
			};
			tim11_ch1_pb9: tim11_ch1_pb9 {
				pinmux = < 0x323 >;
			};
			tim1_ch1n_pb13: tim1_ch1n_pb13 {
				pinmux = < 0x3a1 >;
			};
			tim1_ch2n_pb14: tim1_ch2n_pb14 {
				pinmux = < 0x3c1 >;
			};
			tim1_ch3n_pb15: tim1_ch3n_pb15 {
				pinmux = < 0x3e1 >;
			};
			tim1_ch1n_pe8: tim1_ch1n_pe8 {
				pinmux = < 0x901 >;
			};
			tim1_ch1_pe9: tim1_ch1_pe9 {
				pinmux = < 0x921 >;
			};
			tim1_ch2n_pe10: tim1_ch2n_pe10 {
				pinmux = < 0x941 >;
			};
			tim1_ch2_pe11: tim1_ch2_pe11 {
				pinmux = < 0x961 >;
			};
			tim1_ch3n_pe12: tim1_ch3n_pe12 {
				pinmux = < 0x981 >;
			};
			tim1_ch3_pe13: tim1_ch3_pe13 {
				pinmux = < 0x9a1 >;
				phandle = < 0x14 >;
			};
			tim1_ch4_pe14: tim1_ch4_pe14 {
				pinmux = < 0x9c1 >;
			};
			tim11_ch1_pf7: tim11_ch1_pf7 {
				pinmux = < 0xae3 >;
			};
			tim2_ch1_pa0: tim2_ch1_pa0 {
				pinmux = < 0x1 >;
			};
			tim2_ch2_pa1: tim2_ch2_pa1 {
				pinmux = < 0x21 >;
			};
			tim2_ch3_pa2: tim2_ch3_pa2 {
				pinmux = < 0x41 >;
			};
			tim2_ch4_pa3: tim2_ch4_pa3 {
				pinmux = < 0x61 >;
			};
			tim2_ch1_pa5: tim2_ch1_pa5 {
				pinmux = < 0xa1 >;
			};
			tim2_ch1_pa15: tim2_ch1_pa15 {
				pinmux = < 0x1e1 >;
			};
			tim2_ch2_pb3: tim2_ch2_pb3 {
				pinmux = < 0x261 >;
			};
			tim2_ch3_pb10: tim2_ch3_pb10 {
				pinmux = < 0x341 >;
			};
			tim2_ch4_pb11: tim2_ch4_pb11 {
				pinmux = < 0x361 >;
			};
			tim12_ch1_pb14: tim12_ch1_pb14 {
				pinmux = < 0x3c9 >;
			};
			tim12_ch2_pb15: tim12_ch2_pb15 {
				pinmux = < 0x3e9 >;
			};
			tim13_ch1_pa6: tim13_ch1_pa6 {
				pinmux = < 0xc9 >;
			};
			tim3_ch1_pa6: tim3_ch1_pa6 {
				pinmux = < 0xc2 >;
			};
			tim3_ch2_pa7: tim3_ch2_pa7 {
				pinmux = < 0xe2 >;
			};
			tim3_ch3_pb0: tim3_ch3_pb0 {
				pinmux = < 0x202 >;
			};
			tim3_ch4_pb1: tim3_ch4_pb1 {
				pinmux = < 0x222 >;
			};
			tim3_ch1_pb4: tim3_ch1_pb4 {
				pinmux = < 0x282 >;
			};
			tim3_ch2_pb5: tim3_ch2_pb5 {
				pinmux = < 0x2a2 >;
			};
			tim3_ch1_pc6: tim3_ch1_pc6 {
				pinmux = < 0x4c2 >;
			};
			tim3_ch2_pc7: tim3_ch2_pc7 {
				pinmux = < 0x4e2 >;
			};
			tim3_ch3_pc8: tim3_ch3_pc8 {
				pinmux = < 0x502 >;
			};
			tim3_ch4_pc9: tim3_ch4_pc9 {
				pinmux = < 0x522 >;
			};
			tim13_ch1_pf8: tim13_ch1_pf8 {
				pinmux = < 0xb09 >;
			};
			tim14_ch1_pa7: tim14_ch1_pa7 {
				pinmux = < 0xe9 >;
			};
			tim4_ch1_pb6: tim4_ch1_pb6 {
				pinmux = < 0x2c2 >;
			};
			tim4_ch2_pb7: tim4_ch2_pb7 {
				pinmux = < 0x2e2 >;
			};
			tim4_ch3_pb8: tim4_ch3_pb8 {
				pinmux = < 0x302 >;
			};
			tim4_ch4_pb9: tim4_ch4_pb9 {
				pinmux = < 0x322 >;
			};
			tim4_ch1_pd12: tim4_ch1_pd12 {
				pinmux = < 0x782 >;
			};
			tim4_ch2_pd13: tim4_ch2_pd13 {
				pinmux = < 0x7a2 >;
			};
			tim4_ch3_pd14: tim4_ch3_pd14 {
				pinmux = < 0x7c2 >;
			};
			tim4_ch4_pd15: tim4_ch4_pd15 {
				pinmux = < 0x7e2 >;
			};
			tim14_ch1_pf9: tim14_ch1_pf9 {
				pinmux = < 0xb29 >;
			};
			tim5_ch1_pa0: tim5_ch1_pa0 {
				pinmux = < 0x2 >;
			};
			tim5_ch2_pa1: tim5_ch2_pa1 {
				pinmux = < 0x22 >;
			};
			tim5_ch3_pa2: tim5_ch3_pa2 {
				pinmux = < 0x42 >;
			};
			tim5_ch4_pa3: tim5_ch4_pa3 {
				pinmux = < 0x62 >;
			};
			tim8_ch1n_pa5: tim8_ch1n_pa5 {
				pinmux = < 0xa3 >;
			};
			tim8_ch1n_pa7: tim8_ch1n_pa7 {
				pinmux = < 0xe3 >;
			};
			tim8_ch2n_pb0: tim8_ch2n_pb0 {
				pinmux = < 0x203 >;
			};
			tim8_ch3n_pb1: tim8_ch3n_pb1 {
				pinmux = < 0x223 >;
			};
			tim8_ch2n_pb14: tim8_ch2n_pb14 {
				pinmux = < 0x3c3 >;
			};
			tim8_ch3n_pb15: tim8_ch3n_pb15 {
				pinmux = < 0x3e3 >;
			};
			tim8_ch1_pc6: tim8_ch1_pc6 {
				pinmux = < 0x4c3 >;
			};
			tim8_ch2_pc7: tim8_ch2_pc7 {
				pinmux = < 0x4e3 >;
			};
			tim8_ch3_pc8: tim8_ch3_pc8 {
				pinmux = < 0x503 >;
			};
			tim8_ch4_pc9: tim8_ch4_pc9 {
				pinmux = < 0x523 >;
			};
			tim9_ch1_pa2: tim9_ch1_pa2 {
				pinmux = < 0x43 >;
			};
			tim9_ch2_pa3: tim9_ch2_pa3 {
				pinmux = < 0x63 >;
			};
			tim9_ch1_pe5: tim9_ch1_pe5 {
				pinmux = < 0x8a3 >;
			};
			tim9_ch2_pe6: tim9_ch2_pe6 {
				pinmux = < 0x8c3 >;
			};
			usart1_cts_pa11: usart1_cts_pa11 {
				pinmux = < 0x167 >;
				bias-pull-up;
				drive-open-drain;
			};
			usart2_cts_pa0: usart2_cts_pa0 {
				pinmux = < 0x7 >;
				bias-pull-up;
				drive-open-drain;
			};
			usart2_cts_pd3: usart2_cts_pd3 {
				pinmux = < 0x667 >;
				bias-pull-up;
				drive-open-drain;
				phandle = < 0x7 >;
			};
			usart3_cts_pb13: usart3_cts_pb13 {
				pinmux = < 0x3a7 >;
				bias-pull-up;
				drive-open-drain;
			};
			usart3_cts_pd11: usart3_cts_pd11 {
				pinmux = < 0x767 >;
				bias-pull-up;
				drive-open-drain;
			};
			uart4_cts_pb0: uart4_cts_pb0 {
				pinmux = < 0x208 >;
				bias-pull-up;
				drive-open-drain;
			};
			uart4_cts_pb15: uart4_cts_pb15 {
				pinmux = < 0x3e8 >;
				bias-pull-up;
				drive-open-drain;
			};
			uart5_cts_pc9: uart5_cts_pc9 {
				pinmux = < 0x527 >;
				bias-pull-up;
				drive-open-drain;
			};
			usart6_cts_pg13: usart6_cts_pg13 {
				pinmux = < 0xda8 >;
				bias-pull-up;
				drive-open-drain;
			};
			usart6_cts_pg15: usart6_cts_pg15 {
				pinmux = < 0xde8 >;
				bias-pull-up;
				drive-open-drain;
			};
			uart7_cts_pe10: uart7_cts_pe10 {
				pinmux = < 0x948 >;
				bias-pull-up;
				drive-open-drain;
			};
			uart7_cts_pf9: uart7_cts_pf9 {
				pinmux = < 0xb28 >;
				bias-pull-up;
				drive-open-drain;
			};
			uart8_cts_pd14: uart8_cts_pd14 {
				pinmux = < 0x7c8 >;
				bias-pull-up;
				drive-open-drain;
			};
			usart1_rts_pa12: usart1_rts_pa12 {
				pinmux = < 0x187 >;
				bias-pull-up;
				drive-open-drain;
			};
			usart2_rts_pa1: usart2_rts_pa1 {
				pinmux = < 0x27 >;
				bias-pull-up;
				drive-open-drain;
			};
			usart2_rts_pd4: usart2_rts_pd4 {
				pinmux = < 0x687 >;
				bias-pull-up;
				drive-open-drain;
				phandle = < 0x6 >;
			};
			usart3_rts_pb14: usart3_rts_pb14 {
				pinmux = < 0x3c7 >;
				bias-pull-up;
				drive-open-drain;
			};
			usart3_rts_pd12: usart3_rts_pd12 {
				pinmux = < 0x787 >;
				bias-pull-up;
				drive-open-drain;
			};
			uart4_rts_pa15: uart4_rts_pa15 {
				pinmux = < 0x1e8 >;
				bias-pull-up;
				drive-open-drain;
			};
			uart4_rts_pb14: uart4_rts_pb14 {
				pinmux = < 0x3c8 >;
				bias-pull-up;
				drive-open-drain;
			};
			uart5_rts_pc8: uart5_rts_pc8 {
				pinmux = < 0x507 >;
				bias-pull-up;
				drive-open-drain;
			};
			usart6_rts_pg8: usart6_rts_pg8 {
				pinmux = < 0xd08 >;
				bias-pull-up;
				drive-open-drain;
			};
			usart6_rts_pg12: usart6_rts_pg12 {
				pinmux = < 0xd88 >;
				bias-pull-up;
				drive-open-drain;
			};
			uart7_rts_pe9: uart7_rts_pe9 {
				pinmux = < 0x928 >;
				bias-pull-up;
				drive-open-drain;
			};
			uart7_rts_pf8: uart7_rts_pf8 {
				pinmux = < 0xb08 >;
				bias-pull-up;
				drive-open-drain;
			};
			uart8_rts_pd15: uart8_rts_pd15 {
				pinmux = < 0x7e8 >;
				bias-pull-up;
				drive-open-drain;
			};
			usart1_rx_pa10: usart1_rx_pa10 {
				pinmux = < 0x147 >;
			};
			usart1_rx_pb7: usart1_rx_pb7 {
				pinmux = < 0x2e7 >;
			};
			usart1_rx_pb15: usart1_rx_pb15 {
				pinmux = < 0x3e4 >;
			};
			usart2_rx_pa3: usart2_rx_pa3 {
				pinmux = < 0x67 >;
			};
			usart2_rx_pd6: usart2_rx_pd6 {
				pinmux = < 0x6c7 >;
				phandle = < 0x5 >;
			};
			usart3_rx_pb11: usart3_rx_pb11 {
				pinmux = < 0x367 >;
			};
			usart3_rx_pc11: usart3_rx_pc11 {
				pinmux = < 0x567 >;
			};
			usart3_rx_pd9: usart3_rx_pd9 {
				pinmux = < 0x727 >;
				phandle = < 0x9 >;
			};
			uart4_rx_pa1: uart4_rx_pa1 {
				pinmux = < 0x28 >;
			};
			uart4_rx_pa11: uart4_rx_pa11 {
				pinmux = < 0x166 >;
			};
			uart4_rx_pc11: uart4_rx_pc11 {
				pinmux = < 0x568 >;
			};
			uart4_rx_pd0: uart4_rx_pd0 {
				pinmux = < 0x608 >;
			};
			uart5_rx_pb5: uart5_rx_pb5 {
				pinmux = < 0x2a1 >;
			};
			uart5_rx_pb8: uart5_rx_pb8 {
				pinmux = < 0x307 >;
			};
			uart5_rx_pb12: uart5_rx_pb12 {
				pinmux = < 0x388 >;
			};
			uart5_rx_pd2: uart5_rx_pd2 {
				pinmux = < 0x648 >;
			};
			usart6_rx_pc7: usart6_rx_pc7 {
				pinmux = < 0x4e8 >;
			};
			usart6_rx_pg9: usart6_rx_pg9 {
				pinmux = < 0xd28 >;
				phandle = < 0xb >;
			};
			uart7_rx_pa8: uart7_rx_pa8 {
				pinmux = < 0x10c >;
			};
			uart7_rx_pb3: uart7_rx_pb3 {
				pinmux = < 0x26c >;
			};
			uart7_rx_pe7: uart7_rx_pe7 {
				pinmux = < 0x8e8 >;
			};
			uart7_rx_pf6: uart7_rx_pf6 {
				pinmux = < 0xac8 >;
			};
			uart8_rx_pe0: uart8_rx_pe0 {
				pinmux = < 0x808 >;
			};
			usart1_tx_pa9: usart1_tx_pa9 {
				pinmux = < 0x127 >;
				bias-pull-up;
			};
			usart1_tx_pb6: usart1_tx_pb6 {
				pinmux = < 0x2c7 >;
				bias-pull-up;
			};
			usart1_tx_pb14: usart1_tx_pb14 {
				pinmux = < 0x3c4 >;
				bias-pull-up;
			};
			usart2_tx_pa2: usart2_tx_pa2 {
				pinmux = < 0x47 >;
				bias-pull-up;
			};
			usart2_tx_pd5: usart2_tx_pd5 {
				pinmux = < 0x6a7 >;
				bias-pull-up;
				phandle = < 0x4 >;
			};
			usart3_tx_pb10: usart3_tx_pb10 {
				pinmux = < 0x347 >;
				bias-pull-up;
			};
			usart3_tx_pc10: usart3_tx_pc10 {
				pinmux = < 0x547 >;
				bias-pull-up;
			};
			usart3_tx_pd8: usart3_tx_pd8 {
				pinmux = < 0x707 >;
				bias-pull-up;
				phandle = < 0x8 >;
			};
			uart4_tx_pa0: uart4_tx_pa0 {
				pinmux = < 0x8 >;
				bias-pull-up;
			};
			uart4_tx_pa12: uart4_tx_pa12 {
				pinmux = < 0x186 >;
				bias-pull-up;
			};
			uart4_tx_pc10: uart4_tx_pc10 {
				pinmux = < 0x548 >;
				bias-pull-up;
			};
			uart4_tx_pd1: uart4_tx_pd1 {
				pinmux = < 0x628 >;
				bias-pull-up;
			};
			uart5_tx_pb6: uart5_tx_pb6 {
				pinmux = < 0x2c1 >;
				bias-pull-up;
			};
			uart5_tx_pb9: uart5_tx_pb9 {
				pinmux = < 0x327 >;
				bias-pull-up;
			};
			uart5_tx_pb13: uart5_tx_pb13 {
				pinmux = < 0x3a8 >;
				bias-pull-up;
			};
			uart5_tx_pc12: uart5_tx_pc12 {
				pinmux = < 0x588 >;
				bias-pull-up;
			};
			usart6_tx_pc6: usart6_tx_pc6 {
				pinmux = < 0x4c8 >;
				bias-pull-up;
			};
			usart6_tx_pg14: usart6_tx_pg14 {
				pinmux = < 0xdc8 >;
				bias-pull-up;
				phandle = < 0xa >;
			};
			uart7_tx_pa15: uart7_tx_pa15 {
				pinmux = < 0x1ec >;
				bias-pull-up;
			};
			uart7_tx_pb4: uart7_tx_pb4 {
				pinmux = < 0x28c >;
				bias-pull-up;
			};
			uart7_tx_pe8: uart7_tx_pe8 {
				pinmux = < 0x908 >;
				bias-pull-up;
			};
			uart7_tx_pf7: uart7_tx_pf7 {
				pinmux = < 0xae8 >;
				bias-pull-up;
			};
			uart8_tx_pe1: uart8_tx_pe1 {
				pinmux = < 0x828 >;
				bias-pull-up;
			};
			usb_otg_fs_sof_pa8: usb_otg_fs_sof_pa8 {
				pinmux = < 0x10a >;
			};
			usb_otg_fs_vbus_pa9: usb_otg_fs_vbus_pa9 {
				pinmux = < 0x130 >;
			};
			usb_otg_fs_id_pa10: usb_otg_fs_id_pa10 {
				pinmux = < 0x14a >;
			};
			usb_otg_fs_dm_pa11: usb_otg_fs_dm_pa11 {
				pinmux = < 0x16a >;
				phandle = < 0x16 >;
			};
			usb_otg_fs_dp_pa12: usb_otg_fs_dp_pa12 {
				pinmux = < 0x18a >;
				phandle = < 0x17 >;
			};
			usb_otg_hs_sof_pa4: usb_otg_hs_sof_pa4 {
				pinmux = < 0x8c >;
			};
			usb_otg_hs_id_pb12: usb_otg_hs_id_pb12 {
				pinmux = < 0x38c >;
			};
			usb_otg_hs_vbus_pb13: usb_otg_hs_vbus_pb13 {
				pinmux = < 0x3b0 >;
			};
			usb_otg_hs_dm_pb14: usb_otg_hs_dm_pb14 {
				pinmux = < 0x3cc >;
			};
			usb_otg_hs_dp_pb15: usb_otg_hs_dp_pb15 {
				pinmux = < 0x3ec >;
			};
			usb_otg_hs_ulpi_d0_pa3: usb_otg_hs_ulpi_d0_pa3 {
				pinmux = < 0x6a >;
			};
			usb_otg_hs_ulpi_d1_pb0: usb_otg_hs_ulpi_d1_pb0 {
				pinmux = < 0x20a >;
			};
			usb_otg_hs_ulpi_d2_pb1: usb_otg_hs_ulpi_d2_pb1 {
				pinmux = < 0x22a >;
			};
			usb_otg_hs_ulpi_d7_pb5: usb_otg_hs_ulpi_d7_pb5 {
				pinmux = < 0x2aa >;
			};
			usb_otg_hs_ulpi_d3_pb10: usb_otg_hs_ulpi_d3_pb10 {
				pinmux = < 0x34a >;
			};
			usb_otg_hs_ulpi_d4_pb11: usb_otg_hs_ulpi_d4_pb11 {
				pinmux = < 0x36a >;
			};
			usb_otg_hs_ulpi_d5_pb12: usb_otg_hs_ulpi_d5_pb12 {
				pinmux = < 0x38a >;
			};
			usb_otg_hs_ulpi_d6_pb13: usb_otg_hs_ulpi_d6_pb13 {
				pinmux = < 0x3aa >;
			};
			usb_otg_hs_ulpi_stp_pc0: usb_otg_hs_ulpi_stp_pc0 {
				pinmux = < 0x40a >;
			};
			usb_otg_hs_ulpi_dir_pc2: usb_otg_hs_ulpi_dir_pc2 {
				pinmux = < 0x44a >;
			};
			usb_otg_hs_ulpi_nxt_pc3: usb_otg_hs_ulpi_nxt_pc3 {
				pinmux = < 0x46a >;
			};
		};
		iwdg: watchdog@40003000 {
			compatible = "st,stm32-watchdog";
			reg = < 0x40003000 0x400 >;
			label = "IWDG";
			status = "okay";
		};
		wwdg: watchdog@40002c00 {
			compatible = "st,stm32-window-watchdog";
			reg = < 0x40002c00 0x400 >;
			clocks = < &rcc 0x2 0x800 >;
			label = "WWDG";
			interrupts = < 0x0 0x7 >;
			status = "disabled";
		};
		usart1: serial@40011000 {
			compatible = "st,stm32-usart", "st,stm32-uart";
			reg = < 0x40011000 0x400 >;
			clocks = < &rcc 0x3 0x10 >;
			interrupts = < 0x25 0x0 >;
			status = "disabled";
			label = "UART_1";
		};
		usart2: serial@40004400 {
			compatible = "st,stm32-usart", "st,stm32-uart";
			reg = < 0x40004400 0x400 >;
			clocks = < &rcc 0x2 0x20000 >;
			interrupts = < 0x26 0x0 >;
			status = "disabled";
			label = "UART_2";
			pinctrl-0 = < &usart2_tx_pd5 &usart2_rx_pd6 &usart2_rts_pd4 &usart2_cts_pd3 >;
			pinctrl-names = "default";
			current-speed = < 0x1c200 >;
		};
		usart3: serial@40004800 {
			compatible = "st,stm32-usart", "st,stm32-uart";
			reg = < 0x40004800 0x400 >;
			clocks = < &rcc 0x2 0x40000 >;
			interrupts = < 0x27 0x0 >;
			status = "okay";
			label = "UART_3";
			pinctrl-0 = < &usart3_tx_pd8 &usart3_rx_pd9 >;
			pinctrl-names = "default";
			current-speed = < 0x1c200 >;
		};
		uart4: serial@40004c00 {
			compatible = "st,stm32-uart";
			reg = < 0x40004c00 0x400 >;
			clocks = < &rcc 0x2 0x80000 >;
			interrupts = < 0x34 0x0 >;
			status = "disabled";
			label = "UART_4";
		};
		uart5: serial@40005000 {
			compatible = "st,stm32-uart";
			reg = < 0x40005000 0x400 >;
			clocks = < &rcc 0x2 0x100000 >;
			interrupts = < 0x35 0x0 >;
			status = "disabled";
			label = "UART_5";
		};
		usart6: arduino_serial: serial@40011400 {
			compatible = "st,stm32-usart", "st,stm32-uart";
			reg = < 0x40011400 0x400 >;
			clocks = < &rcc 0x3 0x20 >;
			interrupts = < 0x47 0x0 >;
			status = "okay";
			label = "UART_6";
			pinctrl-0 = < &usart6_tx_pg14 &usart6_rx_pg9 >;
			pinctrl-names = "default";
			current-speed = < 0x1c200 >;
		};
		uart7: serial@40007800 {
			compatible = "st,stm32-uart";
			reg = < 0x40007800 0x400 >;
			clocks = < &rcc 0x2 0x40000000 >;
			interrupts = < 0x52 0x0 >;
			status = "disabled";
			label = "UART_7";
		};
		uart8: serial@40007c00 {
			compatible = "st,stm32-uart";
			reg = < 0x40007c00 0x400 >;
			clocks = < &rcc 0x2 0x80000000 >;
			interrupts = < 0x53 0x0 >;
			status = "disabled";
			label = "UART_8";
		};
		i2c1: arduino_i2c: i2c@40005400 {
			compatible = "st,stm32-i2c-v2";
			clock-frequency = < 0x61a80 >;
			#address-cells = < 0x1 >;
			#size-cells = < 0x0 >;
			reg = < 0x40005400 0x400 >;
			clocks = < &rcc 0x2 0x200000 >;
			interrupts = < 0x1f 0x0 >, < 0x20 0x0 >;
			interrupt-names = "event", "error";
			status = "okay";
			label = "I2C_1";
			pinctrl-0 = < &i2c1_scl_pb8 &i2c1_sda_pb9 >;
			pinctrl-names = "default";
		};
		i2c2: i2c@40005800 {
			compatible = "st,stm32-i2c-v2";
			clock-frequency = < 0x186a0 >;
			#address-cells = < 0x1 >;
			#size-cells = < 0x0 >;
			reg = < 0x40005800 0x400 >;
			clocks = < &rcc 0x2 0x400000 >;
			interrupts = < 0x21 0x0 >, < 0x22 0x0 >;
			interrupt-names = "event", "error";
			status = "disabled";
			label = "I2C_2";
		};
		i2c3: i2c@40005c00 {
			compatible = "st,stm32-i2c-v2";
			clock-frequency = < 0x186a0 >;
			#address-cells = < 0x1 >;
			#size-cells = < 0x0 >;
			reg = < 0x40005c00 0x400 >;
			clocks = < &rcc 0x2 0x800000 >;
			interrupts = < 0x48 0x0 >, < 0x49 0x0 >;
			interrupt-names = "event", "error";
			status = "disabled";
			label = "I2C_3";
		};
		spi1: arduino_spi: spi@40013000 {
			compatible = "st,stm32-spi-fifo", "st,stm32-spi";
			#address-cells = < 0x1 >;
			#size-cells = < 0x0 >;
			reg = < 0x40013000 0x400 >;
			clocks = < &rcc 0x3 0x1000 >;
			interrupts = < 0x23 0x5 >;
			status = "okay";
			label = "SPI_1";
			pinctrl-0 = < &spi1_sck_pa5 &spi1_miso_pa6 &spi1_mosi_pa7 >;
			pinctrl-names = "default";
			cs-gpios = < &gpiod 0xe 0x11 >;
		};
		spi2: spi@40003800 {
			compatible = "st,stm32-spi-fifo", "st,stm32-spi";
			#address-cells = < 0x1 >;
			#size-cells = < 0x0 >;
			reg = < 0x40003800 0x400 >;
			clocks = < &rcc 0x2 0x4000 >;
			interrupts = < 0x24 0x5 >;
			status = "disabled";
			label = "SPI_2";
		};
		spi3: spi@40003c00 {
			compatible = "st,stm32-spi-fifo", "st,stm32-spi";
			#address-cells = < 0x1 >;
			#size-cells = < 0x0 >;
			reg = < 0x40003c00 0x400 >;
			clocks = < &rcc 0x2 0x8000 >;
			interrupts = < 0x33 0x5 >;
			status = "disabled";
			label = "SPI_3";
		};
		spi4: spi@40013400 {
			compatible = "st,stm32-spi-fifo", "st,stm32-spi";
			#address-cells = < 0x1 >;
			#size-cells = < 0x0 >;
			reg = < 0x40013400 0x400 >;
			clocks = < &rcc 0x3 0x2000 >;
			interrupts = < 0x54 0x5 >;
			status = "disabled";
			label = "SPI_4";
		};
		spi5: spi@40015000 {
			compatible = "st,stm32-spi-fifo", "st,stm32-spi";
			#address-cells = < 0x1 >;
			#size-cells = < 0x0 >;
			reg = < 0x40015000 0x400 >;
			clocks = < &rcc 0x3 0x100000 >;
			interrupts = < 0x55 0x5 >;
			status = "disabled";
			label = "SPI_5";
		};
		can1: can@40006400 {
			compatible = "st,stm32-can";
			reg = < 0x40006400 0x400 >;
			interrupts = < 0x13 0x0 >, < 0x14 0x0 >, < 0x15 0x0 >, < 0x16 0x0 >;
			interrupt-names = "TX", "RX0", "RX1", "SCE";
			clocks = < &rcc 0x2 0x2000000 >;
			status = "okay";
			label = "CAN_1";
			sjw = < 0x1 >;
			sample-point = < 0x36b >;
			pinctrl-0 = < &can1_rx_pd0 &can1_tx_pd1 >;
			pinctrl-names = "default";
			bus-speed = < 0x1e848 >;
		};
		timers1: timers@40010000 {
			compatible = "st,stm32-timers";
			reg = < 0x40010000 0x400 >;
			clocks = < &rcc 0x3 0x1 >;
			interrupts = < 0x18 0x0 >, < 0x19 0x0 >, < 0x1a 0x0 >, < 0x1b 0x0 >;
			interrupt-names = "brk", "up", "trgcom", "cc";
			st,prescaler = < 0x2710 >;
			status = "okay";
			label = "TIMERS_1";
			pwm1: pwm {
				compatible = "st,stm32-pwm";
				status = "okay";
				label = "PWM_1";
				#pwm-cells = < 0x3 >;
				pinctrl-0 = < &tim1_ch3_pe13 >;
				pinctrl-names = "default";
			};
		};
		timers2: timers@40000000 {
			compatible = "st,stm32-timers";
			reg = < 0x40000000 0x400 >;
			clocks = < &rcc 0x2 0x1 >;
			interrupts = < 0x1c 0x0 >;
			interrupt-names = "global";
			st,prescaler = < 0x0 >;
			status = "disabled";
			label = "TIMERS_2";
			pwm {
				compatible = "st,stm32-pwm";
				status = "disabled";
				label = "PWM_2";
				#pwm-cells = < 0x3 >;
			};
		};
		timers3: timers@40000400 {
			compatible = "st,stm32-timers";
			reg = < 0x40000400 0x400 >;
			clocks = < &rcc 0x2 0x2 >;
			interrupts = < 0x1d 0x0 >;
			interrupt-names = "global";
			st,prescaler = < 0x0 >;
			status = "disabled";
			label = "TIMERS_3";
			pwm {
				compatible = "st,stm32-pwm";
				status = "disabled";
				label = "PWM_3";
				#pwm-cells = < 0x3 >;
			};
		};
		timers4: timers@40000800 {
			compatible = "st,stm32-timers";
			reg = < 0x40000800 0x400 >;
			clocks = < &rcc 0x2 0x4 >;
			interrupts = < 0x1e 0x0 >;
			interrupt-names = "global";
			st,prescaler = < 0x0 >;
			status = "disabled";
			label = "TIMERS_4";
			pwm {
				compatible = "st,stm32-pwm";
				status = "disabled";
				label = "PWM_4";
				#pwm-cells = < 0x3 >;
			};
		};
		timers5: timers@40000c00 {
			compatible = "st,stm32-timers";
			reg = < 0x40000c00 0x400 >;
			clocks = < &rcc 0x2 0x8 >;
			interrupts = < 0x32 0x0 >;
			interrupt-names = "global";
			st,prescaler = < 0x0 >;
			status = "disabled";
			label = "TIMERS_5";
			pwm {
				compatible = "st,stm32-pwm";
				status = "disabled";
				label = "PWM_5";
				#pwm-cells = < 0x3 >;
			};
		};
		timers6: timers@40001000 {
			compatible = "st,stm32-timers";
			reg = < 0x40001000 0x400 >;
			clocks = < &rcc 0x2 0x10 >;
			interrupts = < 0x36 0x0 >;
			interrupt-names = "global";
			st,prescaler = < 0x0 >;
			status = "disabled";
			label = "TIMERS_6";
		};
		timers7: timers@40001400 {
			compatible = "st,stm32-timers";
			reg = < 0x40001400 0x400 >;
			clocks = < &rcc 0x2 0x20 >;
			interrupts = < 0x37 0x0 >;
			interrupt-names = "global";
			st,prescaler = < 0x0 >;
			status = "disabled";
			label = "TIMERS_7";
		};
		timers8: timers@40010400 {
			compatible = "st,stm32-timers";
			reg = < 0x40010400 0x400 >;
			clocks = < &rcc 0x3 0x2 >;
			interrupts = < 0x2b 0x0 >, < 0x2c 0x0 >, < 0x2d 0x0 >, < 0x2e 0x0 >;
			interrupt-names = "brk", "up", "trgcom", "cc";
			st,prescaler = < 0x0 >;
			status = "disabled";
			label = "TIMERS_8";
			pwm {
				compatible = "st,stm32-pwm";
				status = "disabled";
				label = "PWM_8";
				#pwm-cells = < 0x3 >;
			};
		};
		timers9: timers@40014000 {
			compatible = "st,stm32-timers";
			reg = < 0x40014000 0x400 >;
			clocks = < &rcc 0x3 0x10000 >;
			interrupts = < 0x18 0x0 >;
			interrupt-names = "global";
			st,prescaler = < 0x0 >;
			status = "disabled";
			label = "TIMERS_9";
			pwm {
				compatible = "st,stm32-pwm";
				status = "disabled";
				label = "PWM_9";
				#pwm-cells = < 0x3 >;
			};
		};
		timers10: timers@40014400 {
			compatible = "st,stm32-timers";
			reg = < 0x40014400 0x400 >;
			clocks = < &rcc 0x3 0x20000 >;
			interrupts = < 0x19 0x0 >;
			interrupt-names = "global";
			st,prescaler = < 0x0 >;
			status = "disabled";
			label = "TIMERS_10";
			pwm {
				compatible = "st,stm32-pwm";
				status = "disabled";
				label = "PWM_10";
				#pwm-cells = < 0x3 >;
			};
		};
		timers11: timers@40014800 {
			compatible = "st,stm32-timers";
			reg = < 0x40014800 0x400 >;
			clocks = < &rcc 0x3 0x40000 >;
			interrupts = < 0x1a 0x0 >;
			interrupt-names = "global";
			st,prescaler = < 0x0 >;
			status = "disabled";
			label = "TIMERS_11";
			pwm {
				compatible = "st,stm32-pwm";
				status = "disabled";
				label = "PWM_11";
				#pwm-cells = < 0x3 >;
			};
		};
		timers12: timers@40001800 {
			compatible = "st,stm32-timers";
			reg = < 0x40001800 0x400 >;
			clocks = < &rcc 0x2 0x40 >;
			interrupts = < 0x2b 0x0 >;
			interrupt-names = "global";
			st,prescaler = < 0x0 >;
			status = "disabled";
			label = "TIMERS_12";
			pwm {
				compatible = "st,stm32-pwm";
				status = "disabled";
				label = "PWM_12";
				#pwm-cells = < 0x3 >;
			};
		};
		timers13: timers@40001c00 {
			compatible = "st,stm32-timers";
			reg = < 0x40001c00 0x400 >;
			clocks = < &rcc 0x2 0x80 >;
			interrupts = < 0x2c 0x0 >;
			interrupt-names = "global";
			st,prescaler = < 0x0 >;
			status = "disabled";
			label = "TIMERS_13";
			pwm {
				compatible = "st,stm32-pwm";
				status = "disabled";
				label = "PWM_13";
				#pwm-cells = < 0x3 >;
			};
		};
		timers14: timers@40002000 {
			compatible = "st,stm32-timers";
			reg = < 0x40002000 0x400 >;
			clocks = < &rcc 0x2 0x100 >;
			interrupts = < 0x2d 0x0 >;
			interrupt-names = "global";
			st,prescaler = < 0x0 >;
			status = "disabled";
			label = "TIMERS_14";
			pwm {
				compatible = "st,stm32-pwm";
				status = "disabled";
				label = "PWM_14";
				#pwm-cells = < 0x3 >;
			};
		};
		usbotg_fs: zephyr_udc0: usb@50000000 {
			compatible = "st,stm32-otgfs";
			reg = < 0x50000000 0x40000 >;
			interrupts = < 0x43 0x0 >;
			interrupt-names = "otgfs";
			num-bidir-endpoints = < 0x6 >;
			ram-size = < 0x500 >;
			maximum-speed = "full-speed";
			phys = < &otgfs_phy >;
			clocks = < &rcc 0x1 0x80 >;
			status = "okay";
			label = "OTGFS";
			pinctrl-0 = < &usb_otg_fs_dm_pa11 &usb_otg_fs_dp_pa12 >;
			pinctrl-names = "default";
		};
		usbotg_hs: usb@40040000 {
			compatible = "st,stm32-otghs";
			reg = < 0x40040000 0x40000 >;
			interrupts = < 0x4d 0x0 >, < 0x4a 0x0 >, < 0x4b 0x0 >;
			interrupt-names = "otghs", "ep1_out", "ep1_in";
			num-bidir-endpoints = < 0x9 >;
			ram-size = < 0x1000 >;
			maximum-speed = "full-speed";
			clocks = < &rcc 0x0 0x20000000 >;
			phys = < &otghs_fs_phy >;
			status = "disabled";
			label = "OTGHS";
		};
		rtc: rtc@40002800 {
			compatible = "st,stm32-rtc";
			reg = < 0x40002800 0x300 >;
			interrupts = < 0x29 0x0 >;
			clocks = < &rcc 0x2 0x10000000 >;
			prescaler = < 0x8000 >;
			status = "okay";
			label = "RTC_0";
		};
		adc1: adc@40012000 {
			compatible = "st,stm32-adc";
			reg = < 0x40012000 0x400 >;
			clocks = < &rcc 0x3 0x100 >;
			interrupts = < 0x12 0x0 >;
			status = "okay";
			label = "ADC_1";
			#io-channel-cells = < 0x1 >;
			has-temp-channel;
			has-vref-channel;
			pinctrl-0 = < &adc1_in0_pa0 >;
			pinctrl-names = "default";
		};
		dac1: dac@40007400 {
			compatible = "st,stm32-dac";
			reg = < 0x40007400 0x400 >;
			clocks = < &rcc 0x2 0x20000000 >;
			status = "okay";
			label = "DAC_1";
			#io-channel-cells = < 0x1 >;
			pinctrl-0 = < &dac_out1_pa4 >;
			pinctrl-names = "default";
		};
		dma1: dma@40026000 {
			compatible = "st,stm32-dma-v1";
			#dma-cells = < 0x4 >;
			reg = < 0x40026000 0x400 >;
			interrupts = < 0xb 0x0 0xc 0x0 0xd 0x0 0xe 0x0 0xf 0x0 0x10 0x0 0x11 0x0 0x2f 0x0 >;
			clocks = < &rcc 0x0 0x200000 >;
			status = "disabled";
			label = "DMA_1";
		};
		dma2: dma@40026400 {
			compatible = "st,stm32-dma-v1";
			#dma-cells = < 0x4 >;
			reg = < 0x40026400 0x400 >;
			interrupts = < 0x38 0x0 0x39 0x0 0x3a 0x0 0x3b 0x0 0x3c 0x0 0x44 0x0 0x45 0x0 0x46 0x0 >;
			clocks = < &rcc 0x0 0x400000 >;
			st,mem2mem;
			status = "disabled";
			label = "DMA_2";
		};
		rng: rng@50060800 {
			compatible = "st,stm32-rng";
			reg = < 0x50060800 0x400 >;
			interrupts = < 0x50 0x0 >;
			clocks = < &rcc 0x1 0x40 >;
			status = "okay";
			label = "RNG";
		};
		sdmmc1: sdmmc@40012c00 {
			compatible = "st,stm32-sdmmc";
			reg = < 0x40012c00 0x400 >;
			clocks = < &rcc 0x3 0x800 >;
			interrupts = < 0x31 0x0 >;
			status = "disabled";
			label = "SDMMC_1";
		};
		backup_sram: memory@40024000 {
			compatible = "zephyr,memory-region", "st,stm32-backup-sram";
			reg = < 0x40024000 0x1000 >;
			clocks = < &rcc 0x0 0x40000 >;
			label = "BACKUP_SRAM";
			zephyr,memory-region = "BACKUP_SRAM";
			status = "disabled";
		};
		quadspi: quadspi@a0001000 {
			compatible = "st,stm32-qspi";
			#address-cells = < 0x1 >;
			#size-cells = < 0x0 >;
			reg = < 0xa0001000 0x34 >;
			interrupts = < 0x5c 0x0 >;
			clocks = < &rcc 0x6 0x2 >;
			status = "disabled";
			label = "QUADSPI";
		};
		i2c4: i2c@40006000 {
			compatible = "st,stm32-i2c-v2";
			clock-frequency = < 0x186a0 >;
			#address-cells = < 0x1 >;
			#size-cells = < 0x0 >;
			reg = < 0x40006000 0x400 >;
			clocks = < &rcc 0x2 0x1000000 >;
			interrupts = < 0x5f 0x0 >, < 0x60 0x0 >;
			interrupt-names = "event", "error";
			status = "disabled";
			label = "I2C_4";
		};
		spi6: spi@40015400 {
			compatible = "st,stm32-spi-fifo", "st,stm32-spi";
			#address-cells = < 0x1 >;
			#size-cells = < 0x0 >;
			reg = < 0x40015400 0x400 >;
			clocks = < &rcc 0x3 0x200000 >;
			interrupts = < 0x56 0x5 >;
			status = "disabled";
			label = "SPI_6";
		};
		mac: ethernet@40028000 {
			compatible = "st,stm32-ethernet";
			reg = < 0x40028000 0x8000 >;
			label = "ETH_0";
			interrupts = < 0x3d 0x0 >;
			clock-names = "stmmaceth", "mac-clk-tx", "mac-clk-rx", "mac-clk-ptp";
			clocks = < &rcc 0x0 0x2000000 >, < &rcc 0x0 0x4000000 >, < &rcc 0x0 0x8000000 >, < &rcc 0x0 0x10000000 >;
			status = "okay";
			pinctrl-0 = < &eth_mdc_pc1 &eth_rxd0_pc4 &eth_rxd1_pc5 &eth_ref_clk_pa1 &eth_mdio_pa2 &eth_crs_dv_pa7 &eth_tx_en_pg11 &eth_txd0_pg13 &eth_txd1_pb13 >;
			pinctrl-names = "default";
		};
		sdmmc2: sdmmc@40011c00 {
			compatible = "st,stm32-sdmmc";
			reg = < 0x40011c00 0x400 >;
			clocks = < &rcc 0x3 0x80 >;
			interrupts = < 0x67 0x0 >;
			status = "disabled";
			label = "SDMMC_2";
		};
	};
	cpus {
		#address-cells = < 0x1 >;
		#size-cells = < 0x0 >;
		cpu@0 {
			device_type = "cpu";
			compatible = "arm,cortex-m7";
			reg = < 0x0 >;
			#address-cells = < 0x1 >;
			#size-cells = < 0x1 >;
			mpu: mpu@e000ed90 {
				compatible = "arm,armv7m-mpu";
				reg = < 0xe000ed90 0x40 >;
				arm,num-mpu-regions = < 0x8 >;
			};
		};
	};
	clocks {
		clk_hse: clk-hse {
			#clock-cells = < 0x0 >;
			compatible = "st,stm32-hse-clock";
			status = "okay";
			hse-bypass;
			clock-frequency = < 0x7a1200 >;
			phandle = < 0x24 >;
		};
		clk_hsi: clk-hsi {
			#clock-cells = < 0x0 >;
			compatible = "fixed-clock";
			clock-frequency = < 0xf42400 >;
			status = "disabled";
		};
		clk_lse: clk-lse {
			#clock-cells = < 0x0 >;
			compatible = "fixed-clock";
			clock-frequency = < 0x8000 >;
			status = "disabled";
		};
		clk_lsi: clk-lsi {
			#clock-cells = < 0x0 >;
			compatible = "fixed-clock";
			clock-frequency = < 0x7d00 >;
			status = "disabled";
		};
		pll: pll {
			#clock-cells = < 0x0 >;
			compatible = "st,stm32f7-pll-clock";
			status = "okay";
			div-m = < 0x4 >;
			mul-n = < 0x48 >;
			div-p = < 0x2 >;
			div-q = < 0x3 >;
			clocks = < &clk_hse >;
			phandle = < 0x3 >;
		};
	};
	otghs_fs_phy: otghs_fs_phy {
		compatible = "usb-nop-xceiv";
		#phy-cells = < 0x0 >;
		label = "OTGHS_FS_PHY";
		phandle = < 0x18 >;
	};
	otgfs_phy: otgfs_phy {
		compatible = "usb-nop-xceiv";
		#phy-cells = < 0x0 >;
		label = "OTGFS_PHY";
		phandle = < 0x15 >;
	};
	sram0: memory@20020000 {
		compatible = "mmio-sram";
		reg = < 0x20020000 0x60000 >;
	};
	dtcm: memory@20000000 {
		compatible = "zephyr,memory-region", "arm,dtcm";
		reg = < 0x20000000 0x20000 >;
		zephyr,memory-region = "DTCM";
	};
	arduino_header: connector {
		compatible = "arduino-header-r3";
		#gpio-cells = < 0x2 >;
		gpio-map-mask = < 0xffffffff 0xffffffc0 >;
		gpio-map-pass-thru = < 0x0 0x3f >;
		gpio-map = < 0x0 0x0 &gpioa 0x3 0x0 >, < 0x1 0x0 &gpioc 0x0 0x0 >, < 0x2 0x0 &gpioc 0x3 0x0 >, < 0x3 0x0 &gpiof 0x3 0x0 >, < 0x4 0x0 &gpiof 0x5 0x0 >, < 0x5 0x0 &gpiof 0xa 0x0 >, < 0x6 0x0 &gpiog 0x9 0x0 >, < 0x7 0x0 &gpiog 0xe 0x0 >, < 0x8 0x0 &gpiof 0xf 0x0 >, < 0x9 0x0 &gpioe 0xd 0x0 >, < 0xa 0x0 &gpiof 0xe 0x0 >, < 0xb 0x0 &gpioe 0xb 0x0 >, < 0xc 0x0 &gpioe 0x9 0x0 >, < 0xd 0x0 &gpiof 0xd 0x0 >, < 0xe 0x0 &gpiof 0xc 0x0 >, < 0xf 0x0 &gpiod 0xf 0x0 >, < 0x10 0x0 &gpiod 0xe 0x0 >, < 0x11 0x0 &gpioa 0x7 0x0 >, < 0x12 0x0 &gpioa 0x6 0x0 >, < 0x13 0x0 &gpioa 0x5 0x0 >, < 0x14 0x0 &gpiob 0x9 0x0 >, < 0x15 0x0 &gpiob 0x8 0x0 >;
	};
	leds {
		compatible = "gpio-leds";
		green_led: led_0 {
			gpios = < &gpiob 0x0 0x0 >;
			label = "User LD1";
		};
		blue_led: led_1 {
			gpios = < &gpiob 0x7 0x0 >;
			label = "User LD2";
		};
		red_led: led_2 {
			gpios = < &gpiob 0xe 0x0 >;
			label = "User LD3";
		};
	};
	gpio_keys {
		compatible = "gpio-keys";
		user_button: button_0 {
			label = "User";
			gpios = < &gpioc 0xd 0x1 >;
		};
	};
};
